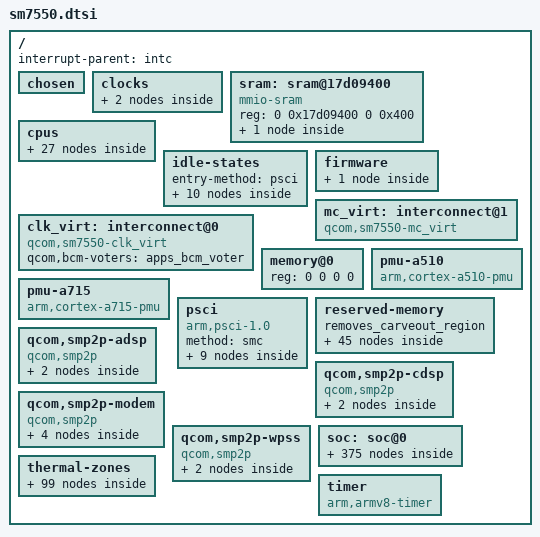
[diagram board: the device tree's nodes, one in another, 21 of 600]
// SPDX-License-Identifier: BSD-3-Clause
/*
 * Copyright (c) 2025, Aditya Choudhury <mail@inferno0230.in>
 */

#include <dt-bindings/clock/qcom,dsi-phy-28nm.h>
#include <dt-bindings/clock/qcom,rpmh.h>
#include <dt-bindings/clock/qcom,sm7550-camcc.h>
#include <dt-bindings/clock/qcom,sm7550-dispcc.h>
#include <dt-bindings/clock/qcom,sm7550-gcc.h>
#include <dt-bindings/clock/qcom,sm7550-gpucc.h>
#include <dt-bindings/clock/qcom,sm7550-tcsr.h>
#include <dt-bindings/clock/qcom,sm7550-videocc.h>
#include <dt-bindings/dma/qcom-gpi.h>
#include <dt-bindings/gpio/gpio.h>
#include <dt-bindings/interconnect/qcom,icc.h>
#include <dt-bindings/interconnect/qcom,sm7550-rpmh.h>
#include <dt-bindings/interrupt-controller/arm-gic.h>
#include <dt-bindings/mailbox/qcom-ipcc.h>
#include <dt-bindings/phy/phy-qcom-qmp.h>
#include <dt-bindings/power/qcom,rpmhpd.h>
#include <dt-bindings/soc/qcom,gpr.h>
#include <dt-bindings/soc/qcom,rpmh-rsc.h>
#include <dt-bindings/sound/qcom,q6dsp-lpass-ports.h>
#include <dt-bindings/thermal/thermal.h>

/ {
	interrupt-parent = <&intc>;

	#address-cells = <2>;
	#size-cells = <2>;

	chosen { };

    clocks {
        xo_board: xo_board {
			compatible = "fixed-clock";
			clock-frequency = <76800000>;
			clock-output-names = "xo_board";
			#clock-cells = <0>;
		};

		sleep_clk: sleep_clk {
			compatible = "fixed-clock";
			clock-frequency = <32000>;
			clock-output-names = "sleep_clk";
			#clock-cells = <0>;
		};
    };

	sram: sram@17d09400 {
		compatible = "mmio-sram";
		reg = <0 0x17d09400 0 0x400>;
		ranges = <0 0 0 0x17d09400 0 0x400>;
		#address-cells = <2>;
		#size-cells = <2>;

		cpu_scp_lpri: scmi-shmem@0 {
			compatible = "arm,scmi-shmem";
			reg = <0 0 0 0x400>;
		};
	};

	cpus {
		#address-cells = <2>;
		#size-cells = <0>;

		cpu0: cpu@0 {
			device_type = "cpu";
			compatible = "arm,cortex-a510";
			reg = <0x0 0x0>;
            clocks = <&cpufreq_hw 0>;
			enable-method = "psci";
			next-level-cache = <&l2_0>;
			power-domains = <&cpu_pd0>;
			power-domain-names = "psci";
			qcom,freq-domain = <&cpufreq_hw 0>;
			next-level-cache = <&l2_0>;
			capacity-dmips-mhz = <1024>;
			dynamic-power-coefficient = <100>;
			#cooling-cells = <2>;
			l2_0: l2-cache {
				compatible = "cache";
				cache-level = <2>;
				cache-unified;
				next-level-cache = <&l3_0>;
				l3_0: l3-cache {
					compatible = "cache";
					cache-level = <3>;
					cache-unified;
				};
			};
		};

		cpu1: cpu@100 {
			device_type = "cpu";
			compatible = "arm,cortex-a510";
			reg = <0x0 0x100>;
			enable-method = "psci";
			clocks = <&cpufreq_hw 0>;
			power-domains = <&cpu_pd1>;
			power-domain-names = "psci";
			qcom,freq-domain = <&cpufreq_hw 0>;
			next-level-cache = <&l2_0>;
			capacity-dmips-mhz = <1024>;
			dynamic-power-coefficient = <100>;
			#cooling-cells = <2>;
		};

		cpu2: cpu@200 {
			device_type = "cpu";
			compatible = "arm,cortex-a510";
			reg = <0x0 0x200>;
			enable-method = "psci";
			clocks = <&cpufreq_hw 0>;
			power-domains = <&CPU_PD2>;
			power-domain-names = "psci";
			qcom,freq-domain = <&cpufreq_hw 0>;
			next-level-cache = <&l2_2>;
			capacity-dmips-mhz = <1024>;
			dynamic-power-coefficient = <100>;
			#cooling-cells = <2>;
			l2_2: l2-cache {
				compatible = "cache";
				cache-level = <2>;
				cache-unified;
				next-level-cache = <&l3_0>;
			};
		};

		cpu3: cpu@300 {
			device_type = "cpu";
			compatible = "arm,cortex-a510";
			reg = <0x0 0x300>;
			enable-method = "psci";
			clocks = <&cpufreq_hw 0>;
			power-domains = <&cpu_pd3>;
			power-domain-names = "psci";
			qcom,freq-domain = <&cpufreq_hw 0>;
			next-level-cache = <&l2_2>;
			capacity-dmips-mhz = <1024>;
			dynamic-power-coefficient = <100>;
			#cooling-cells = <2>;
		};

		cpu4: cpu@400 {
			device_type = "cpu";
			compatible = "arm,cortex-a715";
			reg = <0x0 0x400>;
			enable-method = "psci";
			clocks = <&cpufreq_hw 1>;
			power-domains = <&cpu_pd4>;
			power-domain-names = "psci";
			qcom,freq-domain = <&cpufreq_hw 1>;
			next-level-cache = <&l2_4>;
			capacity-dmips-mhz = <1843>;
			dynamic-power-coefficient = <226>;
			#cooling-cells = <2>;
			l2_4: l2-cache {
				compatible = "cache";
				cache-level = <2>;
				cache-unified;
				next-level-cache = <&l3_0>;
			};
		};

		cpu5: cpu@500 {
			device_type = "cpu";
			compatible = "arm,cortex-a715";
			reg = <0x0 0x500>;
			enable-method = "psci";
			clocks = <&cpufreq_hw 1>;
			power-domains = <&cpu_pd5>;
			power-domain-names = "psci";
			qcom,freq-domain = <&cpufreq_hw 1>;
			next-level-cache = <&l2_5>;
			capacity-dmips-mhz = <1843>;
			dynamic-power-coefficient = <226>;
			#cooling-cells = <2>;
			l2_5: l2-cache {
				compatible = "cache";
				cache-level = <2>;
				cache-unified;
				next-level-cache = <&l3_0>;
			};
		};

		cpu6: cpu@600 {
			device_type = "cpu";
			compatible = "arm,cortex-a715";
			reg = <0x0 0x600>;
			enable-method = "psci";
			clocks = <&cpufreq_hw 1>;
			power-domains = <&cpu_pd6>;
			power-domain-names = "psci";
			qcom,freq-domain = <&cpufreq_hw 1>;
			next-level-cache = <&l2_6>;
			capacity-dmips-mhz = <1843>;
			dynamic-power-coefficient = <226>;
			#cooling-cells = <2>;
			l2_6: l2-cache {
				compatible = "cache";
				cache-level = <2>;
				cache-unified;
				next-level-cache = <&l3_0>;
			};
		};

		cpu7: cpu@700 {
			device_type = "cpu";
			compatible = "arm,cortex-a715";
			reg = <0x0 0x700>;
			enable-method = "psci";
			clocks = <&cpufreq_hw 2>;
			power-domains = <&cpu_pd7>;
			power-domain-names = "psci";
			qcom,freq-domain = <&cpufreq_hw 2>;
			next-level-cache = <&l2_7>;
			capacity-dmips-mhz = <1853>;
			dynamic-power-coefficient = <245>;
			#cooling-cells = <2>;
			l2_7: l2-cache {
				compatible = "cache";
				cache-level = <2>;
				cache-unified;
				next-level-cache = <&l3_0>;
			};
		};

		cpu-map {
			cluster0 {
				core0 {
					cpu = <&cpu0>;
				};

				core1 {
					cpu = <&cpu1>;
				};

				core2 {
					cpu = <&cpu2>;
				};

				core3 {
					cpu = <&cpu3>;
				};
			};

			cluster1 {
				core0 {
					cpu = <&cpu4>;
				};

				core1 {
					cpu = <&cpu5>;
				};

				core2 {
					cpu = <&cpu6>;
				};
			};

			cluster2 {
				core0 {
					cpu = <&cpu7>;
				};
			};
		};
	};

    idle-states {
		entry-method = "psci";

		silver_cpu_sleep_0: cpu-sleep-0-0 {
			compatible = "arm,idle-state";
			idle-state-name = "silver-power-collapse";
			entry-latency-us = <250>;
			exit-latency-us = <900>;
			min-residency-us = <3200>;
			arm,psci-suspend-param = <0x40000003>;
			local-timer-stop;
		};

		silver_cpu_sleep_1: cpu-sleep-0-1 {
			compatible = "arm,idle-state";
			idle-state-name = "silver-rail-power-collapse";
			entry-latency-us = <550>;
			exit-latency-us = <750>;
			min-residency-us = <6700>;
			arm,psci-suspend-param = <0x40000004>;
			local-timer-stop;
		};

		gold_cpu_sleep_0: cpu-sleep-1-0 {
			compatible = "arm,idle-state";
			idle-state-name = "gold-power-collapse";
			entry-latency-us = <400>;
			exit-latency-us = <1100>;
			min-residency-us = <4011>;
			arm,psci-suspend-param = <0x40000003>;
			local-timer-stop;
		};

		gold_cpu_sleep_1: cpu-sleep-1-1 {
			compatible = "arm,idle-state";
			idle-state-name = "gold-rail-power-collapse";
			entry-latency-us = <600>;
			exit-latency-us = <1300>;
			min-residency-us = <8136>;
			arm,psci-suspend-param = <0x40000004>;
			local-timer-stop;
		};

		gold_plus_cpu_sleep_0: cpu-sleep-2-0 {  /* C3 */
			compatible = "arm,idle-state";
			idle-state-name = "gold-plus-power-collapse";
			entry-latency-us = <450>;
			exit-latency-us = <1200>;
			min-residency-us = <6230>;
			arm,psci-suspend-param = <0x40000003>;
			local-timer-stop;
		};

		gold_plus_cpu_sleep_1: cpu-sleep-2-1 {  /* C4 */
			compatible = "arm,idle-state";
			idle-state-name = "gold-plus-rail-power-collapse";
			entry-latency-us = <500>;
			exit-latency-us = <1350>;
			min-residency-us = <7480>;
			arm,psci-suspend-param = <0x40000004>;
			local-timer-stop;
		};

        domain_idle_states {
            cluster_sleep_0: cluster-sleep-0 {
                compatible = "domain-idle-state";
                idle-state-name = "domain-idle-state";
                entry-latency-us = <750>;
                exit-latency-us = <2350>;
                min-residency-us = <9144>;
                arm,psci-suspend-param = <0x41000044>;
            };

            cluster_sleep_1: cluster-sleep-1 {
                compatible = "domain-idle-state";
                idle-state-name = "cx-ret";
                entry-latency-us = <1561>;
                exit-latency-us = <2801>;
                min-residency-us = <8550>;
                arm,psci-suspend-param = <0x41001344>;
            };

            cluster_sleep_2: cluster-sleep-2 {
                compatible = "domain-idle-state";
                idle-state-name = "domain-idle-state";
                entry-latency-us = <2800>;
                exit-latency-us = <4400>;
                min-residency-us = <10150>;
                arm,psci-suspend-param = <0x4100b344>;
            };

        };
	};

    firmware {
        scm: scm {
            compatible = "qcom,scm-sm7550", "qcom,scm";
            qcom,dload-mode = <&tcsr 0x19000>;
        };
    };

	clk_virt: interconnect@0 {
		compatible = "qcom,sm7550-clk_virt";
		#interconnect-cells = <1>;
		qcom,bcm-voters = <&apps_bcm_voter>;
	};

	mc_virt: interconnect@1 {
		compatible = "qcom,sm7550-mc_virt";
		#interconnect-cells = <1>;
		qcom,bcm-voters = <&apps_bcm_voter>, <&disp_bcm_voter>;
	};

	memory@0 {
		device_type = "memory";
		/* We expect the bootloader to fill in the size */
		reg = <0 0 0 0>;
	};

	pmu-a510 {
		compatible = "arm,cortex-a510-pmu";
		interrupts = <GIC_PPI 7 IRQ_TYPE_LEVEL_LOW &ppi_cluster0>;
	};

	pmu-a715 {
		compatible = "arm,cortex-a715-pmu";
		interrupts = <GIC_PPI 7 IRQ_TYPE_LEVEL_LOW &ppi_cluster1>;
	};

	psci {
		compatible = "arm,psci-1.0";
		method = "smc";

		cpu_pd0: power-domain-cpu0 {
			#power-domain-cells = <0>;
			power-domains = <&cluster_pd>;
            domain-idle-states = <&silver_cpu_sleep_0>, <&silver_cpu_sleep_1>;
		};

		cpu_pd1: power-domain-cpu1 {
			#power-domain-cells = <0>;
			power-domains = <&cluster_pd>;
            domain-idle-states = <&silver_cpu_sleep_0>, <&silver_cpu_sleep_1>;
		};

		cpu_pd2: power-domain-cpu2 {
			#power-domain-cells = <0>;
			power-domains = <&cluster_pd>;
            domain-idle-states = <&silver_cpu_sleep_0>, <&silver_cpu_sleep_1>;
		};

		cpu_pd3: power-domain-cpu3 {
			#power-domain-cells = <0>;
			power-domains = <&cluster_pd>;
            domain-idle-states = <&silver_cpu_sleep_0>, <&silver_cpu_sleep_1>;
		};

		cpu_pd4: power-domain-cpu4 {
			#power-domain-cells = <0>;
			power-domains = <&cluster_pd>;
            domain-idle-states = <&gold_cpu_sleep_0>, <&gold_cpu_sleep_1>;
		};

		cpu_pd5: power-domain-cpu5 {
			#power-domain-cells = <0>;
			power-domains = <&cluster_pd>;
            domain-idle-states = <&gold_cpu_sleep_0>, <&gold_cpu_sleep_1>;
		};

		cpu_pd6: power-domain-cpu6 {
			#power-domain-cells = <0>;
			power-domains = <&cluster_pd>;
            domain-idle-states = <&gold_cpu_sleep_0>, <&gold_cpu_sleep_1>;
		};

		cpu_pd7: power-domain-cpu7 {
			#power-domain-cells = <0>;
			power-domains = <&cluster_pd>;
            domain-idle-states = <&gold_plus_cpu_sleep_0>, <&gold_plus_cpu_sleep_1>;
		};

		cluster_pd: power-domain-cluster {
			#power-domain-cells = <0>;
			domain-idle-states = <&cluster_sleep_0>, <&cluster_sleep_1>, <&cluster_sleep_2>;
		};
	};

    reserved-memory {
        #address-cells = <2>;
        #size-cells = <2>;
        ranges;
        removes_carveout_region;

        gunyah_hyp_mem: gunyah_hyp_region@80000000 {
            no-map;
            reg = <0x0 0x80000000 0x0 0xa00000>;
        };

        cpusys_vm_mem: cpusys_vm_region@80a00000 {
            no-map;
            reg = <0x0 0x80a00000 0x0 0x400000>;
        };

        hyp_tags_mem: hyp_tags_region@80e00000 {
            no-map;
            reg = <0x0 0x80e00000 0x0 0x3d0000>;
        };

        hyp_reserved_mem: hyp_reserved_region@811d0000 {
            no-map;
            reg = <0x0 0x811d0000 0x0 0x30000>;
        };

        xbl_dtlog_mem: xbl_dtlog_region@81a00000 {
            no-map;
            reg = <0x0 0x81a00000 0x0 0x40000>;
        };

        xbl_ramdump_mem: xbl_ramdump_region@81a40000 {
            no-map;
            reg = <0x0 0x81a40000 0x0 0x1c0000>;
        };

        aop_image_mem: aop_image_region@81c00000 {
            no-map;
            reg = <0x0 0x81c00000 0x0 0x60000>;
        };

        aop_cmd_db_mem: aop_cmd_db_region@81c60000 {
            compatible = "qcom,cmd-db";
            no-map;
            reg = <0x0 0x81c60000 0x0 0x20000>;
        };

        aop_config_mem: aop_config_region@81c80000 {
            no-map;
            reg = <0x0 0x81c80000 0x0 0x20000>;
        };

        tme_crash_dump_mem: tme_crash_dump_region@81ca0000 {
            no-map;
            reg = <0x0 0x81ca0000 0x0 0x40000>;
        };

        tme_log_mem: tme_log_region@81ce0000 {
            no-map;
            reg = <0x0 0x81ce0000 0x0 0x4000>;
        };

        uefi_log_mem: uefi_log_region@81ce4000 {
            no-map;
            reg = <0x0 0x81ce4000 0x0 0x10000>;
        };

        chipinfo_mem: chipinfo_region@81cf4000 {
            no-map;
            reg = <0x0 0x81cf4000 0x0 0x1000>;
        };

        smem_mem: smem_region@81d00000 {
            no-map;
            reg = <0x0 0x81d00000 0x0 0x200000>;
        };

        adsp_mhi_mem: adsp_mhi_region@81f00000 {
            no-map;
            reg = <0x0 0x81f00000 0x0 0x20000>;
        };

        global_sync_mem: global_sync_region@82600000 {
            no-map;
            reg = <0x0 0x82600000 0x0 0x100000>;
        };

        tz_stat_mem: tz_stat_region@82700000 {
            no-map;
            reg = <0x0 0x82700000 0x0 0x100000>;
        };

        wlan_msa_moselle_mem: wlan_msa_moselle_region@82800000 {
            no-map;
            reg = <0x0 0x82800000 0x0 0xc00000>;
        };

        mpss_mem: mpss_region@8a800000 {
            no-map;
            reg = <0x0 0x8a800000 0x0 0x11800000>;
        };

        q6_mpss_dtb_mem: q6_mpss_dtb_region@9c000000 {
            no-map;
            reg = <0x0 0x9c000000 0x0 0x80000>;
        };

        ipa_fw_mem: ipa_fw_region@9c080000 {
            no-map;
            reg = <0x0 0x9c080000 0x0 0x10000>;
        };

        ipa_gsi_mem: ipa_gsi_region@9c090000 {
            no-map;
            reg = <0x0 0x9c090000 0x0 0xa000>;
        };

        gpu_microcode_mem: gpu_microcode_region@9c09a000 {
            no-map;
            reg = <0x0 0x9c09a000 0x0 0x2000>;
        };

        q6_adsp_dtb_mem: q6_adsp_dtb_region@9c180000 {
            no-map;
            reg = <0x0 0x9c180000 0x0 0x80000>;
        };

        adsp_mem: adsp_region@9c200000 {
            no-map;
            reg = <0x0 0x9c200000 0x0 0x2900000>;
        };

        camera_mem: camera_region@a1b00000 {
            no-map;
            reg = <0x0 0xa1b00000 0x0 0x800000>;
        };

        video_mem: video_region@9f000000 {
            no-map;
            reg = <0x0 0x9f000000 0x0 0x700000>;
        };

        wpss_moselle_mem: wpss_moselle_region@9f700000 {
            no-map;
            reg = <0x0 0x9f700000 0x0 0x1900000>;
        };

        cdsp_mem: cdsp_region@a1000000 {
            no-map;
            reg = <0x0 0xa1000000 0x0 0xa80000>;
        };

        q6_cdsp_dtb_mem: q6_cdsp_dtb_region@a1a80000 {
            no-map;
            reg = <0x0 0xa1a80000 0x0 0x80000>;
        };

        tz_reserved_mem: tz_reserved_region@d8000000 {
            no-map;
            reg = <0x0 0xd8000000 0x0 0x100000>;
        };

        xbl_sc_mem: xbl_sc_region@d8100000 {
            no-map;
            reg = <0x0 0xd8100000 0x0 0x40000>;
        };

        cpucp_fw_mem: cpucp_fw_region@d8140000 {
            no-map;
            reg = <0x0 0xd8140000 0x0 0x1c0000>;
        };

        qtee_mem: qtee_region@d8300000 {
            no-map;
            reg = <0x0 0xd8300000 0x0 0x500000>;
        };

        ta_mem: ta_region@d8800000 {
            no-map;
            reg = <0x0 0xd8800000 0x0 0x1a00000>;
        };

        tz_tags_mem: tz_tags_region@da200000 {
            no-map;
            reg = <0x0 0xda200000 0x0 0x680000>;
        };

        trust_ui_vm_mem: trust_ui_vm_region@f3800000 {
            no-map;
            reg = <0x0 0xf3800000 0x0 0x40ee000>;
        };

        trust_ui_vm_dump: trust_ui_vm_dump@0xf78ee000 {
            no-map;
            reg = <0x0 0xf78ee000 0x0 0x1000>;
        };

        trust_ui_vm_qrtr: trust_ui_vm_qrtr@0xf78ef000 {
            no-map;
            reg = <0x0 0xf78ef000 0x0 0x9000>;
        };

        trust_ui_vm_vblk0_ring: trust_ui_vm_vblk0_ring@0xf78f8000 {
            no-map;
            reg = <0x0 0xf78f8000 0x0 0x4000>;
            gunyah-label = <0x11>;
        };

        trust_ui_vm_vblk1_ring: trust_ui_vm_vblk1_ring@0xf78fc000 {
            no-map;
            reg = <0x0 0xf78fc000 0x0 0x4000>;
            gunyah-label = <0x10>;
        };

        trust_ui_vm_swiotlb: trust_ui_vm_swiotlb@0xf7900000 {
            no-map;
            reg = <0x0 0xf7900000 0x0 0x100000>;
            gunyah-label = <0x12>;
        };

        oem_vm_vblk0_ring: oem_vm_vblk0_ring@f7afc000 {
            no-map;
            reg = <0x0 0xf7afc000 0x0 0x4000>;
            gunyah-label = <0x13>;
        };

        oem_vm_swiotlb: oem_vm_swiotlb@f7b00000 {
            no-map;
            reg = <0x0 0xf7b00000 0x0 0x100000>;
            gunyah-label = <0x14>;
        };

        oem_vm_mem: oem_vm_region@f7c00000 {
            compatible = "shared-dma-pool";
            reg = <0x0 0xf7c00000 0x0 0x4800000>;
            reusable;
            alignment = <0x0 0x400000>;
        };
    };

	qcom,smp2p-adsp {
		compatible = "qcom,smp2p";
		qcom,smem = <443>, <429>;
		interrupt-parent = <&ipcc_mproc>;
		interrupts = <IPCC_CLIENT_LPASS 
                      IPCC_MPROC_SIGNAL_SMP2P
			          IRQ_TYPE_EDGE_RISING>;
		mboxes = <&ipcc_mproc IPCC_CLIENT_LPASS
			  IPCC_MPROC_SIGNAL_SMP2P>;
		qcom,local-pid = <0>;
		qcom,remote-pid = <2>;

		adsp_smp2p_out: master-kernel {
			qcom,entry-name = "master-kernel";
			#qcom,smem-state-cells = <1>;
		};

		adsp_smp2p_in: slave-kernel {
			qcom,entry-name = "slave-kernel";
			interrupt-controller;
			#interrupt-cells = <2>;
		};
	};

	qcom,smp2p-cdsp {
		compatible = "qcom,smp2p";
		qcom,smem = <94>, <432>;
		interrupt-parent = <&ipcc_mproc>;
		interrupts = <IPCC_CLIENT_CDSP IPCC_MPROC_SIGNAL_SMP2P
			      IRQ_TYPE_EDGE_RISING>;
		mboxes = <&ipcc_mproc IPCC_CLIENT_CDSP IPCC_MPROC_SIGNAL_SMP2P>;
		qcom,local-pid = <0>;
		qcom,remote-pid = <5>;

		cdsp_smp2p_out: master-kernel {
			qcom,entry-name = "master-kernel";
			#qcom,smem-state-cells = <1>;
		};

		cdsp_smp2p_in: slave-kernel {
			qcom,entry-name = "slave-kernel";
			interrupt-controller;
			#interrupt-cells = <2>;
		};
	};

	qcom,smp2p-modem {
		compatible = "qcom,smp2p";
		qcom,smem = <435>, <428>;
		interrupt-parent = <&ipcc_mproc>;
		interrupts = <IPCC_CLIENT_MPSS IPCC_MPROC_SIGNAL_SMP2P
			      IRQ_TYPE_EDGE_RISING>;
		mboxes = <&ipcc_mproc IPCC_CLIENT_MPSS IPCC_MPROC_SIGNAL_SMP2P>;
		qcom,local-pid = <0>;
		qcom,remote-pid = <1>;

		modem_smp2p_out: master-kernel {
			qcom,entry-name = "master-kernel";
			#qcom,smem-state-cells = <1>;
		};

		modem_smp2p_in: slave-kernel {
			qcom,entry-name = "slave-kernel";
			interrupt-controller;
			#interrupt-cells = <2>;
		};

		smp2p_ipa_out: ipa-ap-to-modem {
			qcom,entry-name = "ipa";
			#qcom,smem-state-cells = <1>;
		};

		smp2p_ipa_in: ipa-modem-to-ap {
			qcom,entry-name = "ipa";
			interrupt-controller;
			#interrupt-cells = <2>;
		};
	};
	qcom,smp2p-wpss {
		compatible = "qcom,smp2p";
		qcom,smem = <617>, <616>;
		interrupt-parent = <&ipcc_mproc>;
		interrupts = <IPCC_CLIENT_WPSS IPCC_MPROC_SIGNAL_SMP2P
			IRQ_TYPE_EDGE_RISING>;
		mboxes = <&ipcc_mproc IPCC_CLIENT_WPSS IPCC_MPROC_SIGNAL_SMP2P>;
		qcom,local-pid = <0>;
		qcom,remote-pid = <13>;

		wpss_smp2p_out: master-kernel {
			qcom,entry-name = "master-kernel";
			#qcom,smem-state-cells = <1>;
		};

		wpss_smp2p_in: slave-kernel {
			qcom,entry-name = "slave-kernel";
			interrupt-controller;
			#interrupt-cells = <2>;
		};
	};

    soc: soc@0 {
        gcc: clock-controller@100000 {
            compatible = "qcom,sm7550-gcc";
            reg = <0 0x100000 0 0x1f4200>;
            clocks = <&rpmhcc RPMH_CXO_CLK>,
                <&pcie_0_pipe_clk>,
                <&pcie_1_phy_aux_clk>,
                <&pcie_1_pipe_clk>,
                <&sleep_clk>,
                <&ufs_phy_rx_symbol_0_clk>,
                <&ufs_phy_rx_symbol_1_clk>,
                <&ufs_phy_tx_symbol_0_clk>,
                <&usb3_phy_wrapper_gcc_usb30_pipe_clk>;
            #clock-cells = <1>;
            #reset-cells = <1>;
        };

        ipcc: mailbox@408000 {
            compatible = "qcom,sm7550-ipcc";
            reg = <0 0x408000 0 0x1000>;
            interrupts = <GIC_SPI 229 IRQ_TYPE_LEVEL_HIGH 0>;
            interrupt-controller;
            #interrupt-cells = <3>;
            #mbox-cells = <2>;
        };

        gpi_dma0: dma-controller@800000  {
            compatible = "qcom,sm7550-gpi-dma";
            #dma-cells = <5>;
            reg = <0 0x800000 0 0x60000>;
            interrupts = <GIC_SPI 588 IRQ_TYPE_LEVEL_HIGH>,
                <GIC_SPI 589 IRQ_TYPE_LEVEL_HIGH>,
                <GIC_SPI 590 IRQ_TYPE_LEVEL_HIGH>,
                <GIC_SPI 591 IRQ_TYPE_LEVEL_HIGH>,
                <GIC_SPI 592 IRQ_TYPE_LEVEL_HIGH>,
                <GIC_SPI 593 IRQ_TYPE_LEVEL_HIGH>,
                <GIC_SPI 594 IRQ_TYPE_LEVEL_HIGH>,
                <GIC_SPI 595 IRQ_TYPE_LEVEL_HIGH>,
                <GIC_SPI 596 IRQ_TYPE_LEVEL_HIGH>,
                <GIC_SPI 597 IRQ_TYPE_LEVEL_HIGH>,
                <GIC_SPI 598 IRQ_TYPE_LEVEL_HIGH>,
                <GIC_SPI 599 IRQ_TYPE_LEVEL_HIGH>;
            dma-channels = <12>;
            dma-channel-mask = <0x1E>;
            iommus = <&apps_smmu 0x436 0x0>;
            dma-coherent;
            status = "disabled";
        };

        gpi_dma1: dma-controller@a00000  {
            compatible = "qcom,sm7550-gpi-dma";
            #dma-cells = <5>;
            reg = <0 0xa00000 0 0x60000>;
            interrupts = <GIC_SPI 279 IRQ_TYPE_LEVEL_HIGH 0>,
                <GIC_SPI 280 IRQ_TYPE_LEVEL_HIGH 0>,
                <GIC_SPI 281 IRQ_TYPE_LEVEL_HIGH 0>,
                <GIC_SPI 282 IRQ_TYPE_LEVEL_HIGH 0>,
                <GIC_SPI 283 IRQ_TYPE_LEVEL_HIGH 0>,
                <GIC_SPI 284 IRQ_TYPE_LEVEL_HIGH 0>,
                <GIC_SPI 293 IRQ_TYPE_LEVEL_HIGH 0>,
                <GIC_SPI 294 IRQ_TYPE_LEVEL_HIGH 0>,
                <GIC_SPI 295 IRQ_TYPE_LEVEL_HIGH 0>,
                <GIC_SPI 296 IRQ_TYPE_LEVEL_HIGH 0>,
                <GIC_SPI 297 IRQ_TYPE_LEVEL_HIGH 0>,
                <GIC_SPI 298 IRQ_TYPE_LEVEL_HIGH 0>;
            dma-channels = <12>;
            dma-channel-mask = <0x3f>;
            iommus = <&apps_smmu 0x36 0x0>;
            dma-coherent;
            status = "disabled";
        };

        qupv3_id_0: geniqup@8c0000 {
            compatible = "qcom,geni-se-qup";
            reg = <0 0x8c0000 0 0x2000>;
			ranges;
            clock-names = "m-ahb", "s-ahb";
            clocks = <&gcc GCC_QUPV3_WRAP_0_M_AHB_CLK>,
                <&gcc GCC_QUPV3_WRAP_0_S_AHB_CLK>;
            iommus = <&apps_smmu 0x423 0x0>;
            dma-coherent;
            #address-cells = <2>;
			#size-cells = <2>;
            status = "disabled";

            i2c0: i2c@880000 {
                compatible = "qcom,geni-i2c";
                reg = <0 0x880000 0 0x4000>;
                interrupts = <GIC_SPI 373 IRQ_TYPE_LEVEL_HIGH 0>;
                clock-names = "se";
                clocks = <&gcc GCC_QUPV3_WRAP0_S0_CLK>;
                interconnects = <&clk_virt MASTER_QUP_CORE_0 &clk_virt SLAVE_QUP_CORE_0>,
                                <&gem_noc MASTER_APPSS_PROC &config_noc SLAVE_QUP_0>,
                                <&aggre2_noc MASTER_QUP_0 &mc_virt SLAVE_EBI1>;
                interconnect-names = "qup-core", "qup-config", "qup-memory";
                dmas = <&gpi_dma0 0 0 QCOM_GPI_I2C>,
                    <&gpi_dma0 1 0 QCOM_GPI_I2C>;
                dma-names = "tx", "rx";
                pinctrl-0 = <&qup_i2c0_data_clk>;
                pinctrl-names = "default", "sleep";
                #address-cells = <1>;
                #size-cells = <0>;

                status = "disabled";
            };

            spi0: spi@880000 {
                compatible = "qcom,geni-spi";
                reg = <0 0x880000 0 0x4000>;
                interrupts = <GIC_SPI 373 IRQ_TYPE_LEVEL_HIGH 0>;
                clock-names = "se";
                clocks = <&gcc GCC_QUPV3_WRAP0_S0_CLK>;
                interconnects =
                <&clk_virt MASTER_QUP_CORE_0 &clk_virt SLAVE_QUP_CORE_0>,
                <&gem_noc MASTER_APPSS_PROC &config_noc SLAVE_QUP_0>,
                <&aggre2_noc MASTER_QUP_0 &mc_virt  SLAVE_EBI1>;
                interconnect-names = "qup-core", "qup-config", "qup-memory";
                dmas = <&gpi_dma0 0 0 QCOM_GPI_SPI>,
                    <&gpi_dma0 1 0 QCOM_GPI_SPI>;
                dma-names = "tx", "rx";
                pinctrl-names = "default", "sleep";
                pinctrl-0 = <&qup_spi0_data_clk>, <&qup_spi0_cs>;

                #address-cells = <1>;
                #size-cells = <0>;

                status = "disabled";
            };

            i2c1: i2c@884000 {
                compatible = "qcom,geni-i2c";
                reg = <0 0x884000 0 0x4000>;
                interrupts = <GIC_SPI 583 IRQ_TYPE_LEVEL_HIGH 0>;
                clock-names = "se";
                clocks = <&gcc GCC_QUPV3_WRAP0_S1_CLK>;
                interconnects = 
                <&clk_virt MASTER_QUP_CORE_0 &clk_virt SLAVE_QUP_CORE_0>,
    			<&gem_noc MASTER_APPSS_PROC &config_noc SLAVE_QUP_0>,
	    		<&aggre2_noc MASTER_QUP_0 &mc_virt  SLAVE_EBI1>;
                interconnect-names = "qup-core", "qup-config", "qup-memory";
                dmas = <&gpi_dma0 0 1 QCOM_GPI_I2C>,
                    <&gpi_dma0 1 1 QCOM_GPI_I2C>;
                dma-names = "tx", "rx";
                pinctrl-0 = <&qup_i2c1_data_clk>;
                pinctrl-names = "default", "sleep";
                #address-cells = <1>;
                #size-cells = <0>;

                status = "disabled";
            };

            spi1: spi@884000 {
                compatible = "qcom,geni-spi";
                reg = <0 884000 0 0x4000>;
                interrupts = <GIC_SPI 583 IRQ_TYPE_LEVEL_HIGH 0>;
                clock-names = "se";
                clocks = <&gcc GCC_QUPV3_WRAP0_S1_CLK>;
                interconnects =
		    	<&clk_virt MASTER_QUP_CORE_0 &clk_virt SLAVE_QUP_CORE_0>,
		    	<&gem_noc MASTER_APPSS_PROC &config_noc SLAVE_QUP_0>,
		    	<&aggre2_noc MASTER_QUP_0 &mc_virt  SLAVE_EBI1>;
                interconnect-names = "qup-core", "qup-config", "qup-memory";
                dmas = <&gpi_dma0 0 1 QCOM_GPI_SPI>,
                    <&gpi_dma0 1 1 QCOM_GPI_SPI>;
                dma-names = "tx", "rx";
                pinctrl-names = "default", "sleep";
                pinctrl-0 = <&qup_spi1_data_clk>, <&qup_spi1_cs>;

                #address-cells = <1>;
                #size-cells = <0>;

                status = "disabled";
            };

            i2c2: i2c@888000 {
                compatible = "qcom,geni-i2c";
                reg = <0 888000 0 0x4000>;
                interrupts = <GIC_SPI 584 IRQ_TYPE_LEVEL_HIGH 0>;
                clock-names = "se";
                clocks = <&gcc GCC_QUPV3_WRAP0_S2_CLK>;
                interconnects = 
			    <&clk_virt MASTER_QUP_CORE_0 &clk_virt SLAVE_QUP_CORE_0>,
			    <&gem_noc MASTER_APPSS_PROC &config_noc SLAVE_QUP_0>,
			    <&aggre2_noc MASTER_QUP_0 &mc_virt  SLAVE_EBI1>;
                interconnect-names = "qup-core", "qup-config", "qup-memory";
                dmas = <&gpi_dma0 0 2 QCOM_GPI_I2C>,
                    <&gpi_dma0 1 2 QCOM_GPI_I2C>;
                dma-names = "tx", "rx";
                pinctrl-0 = <&qup_i2c2_data_clk>;
                pinctrl-names = "default", "sleep";
                #address-cells = <1>;
                #size-cells = <0>;

                status = "disabled";
            };

            spi2: spi@888000 {
                compatible = "qcom,geni-spi";
                reg = <0 888000 0 0x4000>;
                interrupts = <GIC_SPI 584 IRQ_TYPE_LEVEL_HIGH 0>;
                clock-names = "se";
                clocks = <&gcc GCC_QUPV3_WRAP0_S2_CLK>;
                interconnects =
                <&clk_virt MASTER_QUP_CORE_0 &clk_virt SLAVE_QUP_CORE_0>,
                <&gem_noc MASTER_APPSS_PROC &config_noc SLAVE_QUP_0>,
                <&aggre2_noc MASTER_QUP_0 &mc_virt  SLAVE_EBI1>;
                interconnect-names = "qup-core", "qup-config", "qup-memory";
                dmas = <&gpi_dma0 0 2 QCOM_GPI_SPI>,
                    <&gpi_dma0 1 2 QCOM_GPI_SPI>;
                dma-names = "tx", "rx";
                pinctrl-names = "default", "sleep";
                pinctrl-0 = <&qup_spi2_data_clk>, <&qup_spi2_cs>;

                #address-cells = <1>;
                #size-cells = <0>;

                status = "disabled";
            };

            i2c3: i2c@88c000 {
                compatible = "qcom,geni-i2c";
                reg = <0 88c000 0 0x4000>;
                interrupts = <GIC_SPI 585 IRQ_TYPE_LEVEL_HIGH 0>;
                clock-names = "se";
                clocks = <&gcc GCC_QUPV3_WRAP0_S3_CLK>;
                interconnects = 
                <&clk_virt MASTER_QUP_CORE_0 &clk_virt SLAVE_QUP_CORE_0>,
                <&gem_noc MASTER_APPSS_PROC &config_noc SLAVE_QUP_0>,
                <&aggre2_noc MASTER_QUP_0 &mc_virt  SLAVE_EBI1>;
                interconnect-names = "qup-core", "qup-config", "qup-memory";
                dmas = <&gpi_dma0 0 3 QCOM_GPI_I2C>,
                    <&gpi_dma0 1 3 QCOM_GPI_I2C>;
                dma-names = "tx", "rx";
                pinctrl-0 = <&qup_i2c3_data_clk>;
                pinctrl-names = "default", "sleep";
                #address-cells = <1>;
                #size-cells = <0>;

                status = "disabled";
            };

            spi3: spi@88c000 {
                compatible = "qcom,geni-spi";
                reg = <0 88c000 0 0x4000>;
                interrupts = <GIC_SPI 585 IRQ_TYPE_LEVEL_HIGH 0>;
                clock-names = "se";
                clocks = <&gcc GCC_QUPV3_WRAP0_S3_CLK>;
                interconnects =
                <&clk_virt MASTER_QUP_CORE_0 &clk_virt SLAVE_QUP_CORE_0>,
                <&gem_noc MASTER_APPSS_PROC &config_noc SLAVE_QUP_0>,
                <&aggre2_noc MASTER_QUP_0 &mc_virt  SLAVE_EBI1>;
                interconnect-names = "qup-core", "qup-config", "qup-memory";
                dmas = <&gpi_dma0 0 3 QCOM_GPI_SPI>,
                    <&gpi_dma0 1 3 QCOM_GPI_SPI>;
                dma-names = "tx", "rx";
                pinctrl-names = "default", "sleep";
                pinctrl-0 = <&qup_spi3_data_clk>, <&qup_spi3_cs>;

                #address-cells = <1>;
                #size-cells = <0>;

                status = "disabled";
            };

            i2c4: i2c@890000 {
                compatible = "qcom,geni-i2c";
                reg = <0 890000 0 0x4000>;
                interrupts = <GIC_SPI 586 IRQ_TYPE_LEVEL_HIGH 0>;
                clock-names = "se";
                clocks = <&gcc GCC_QUPV3_WRAP0_S4_CLK>;
                interconnects = 
		    	<&clk_virt MASTER_QUP_CORE_0 &clk_virt SLAVE_QUP_CORE_0>,
		    	<&gem_noc MASTER_APPSS_PROC &config_noc SLAVE_QUP_0>,
			    <&aggre2_noc MASTER_QUP_0 &mc_virt  SLAVE_EBI1>;
                interconnect-names = "qup-core", "qup-config", "qup-memory";
                dmas = <&gpi_dma0 0 4 QCOM_GPI_I2C>,
                    <&gpi_dma0 1 4 QCOM_GPI_I2C>;
                dma-names = "tx", "rx";
                pinctrl-0 = <&qup_i2c4_data_clk>;
                pinctrl-names = "default", "sleep";
                #address-cells = <1>;
                #size-cells = <0>;

                status = "disabled";
            };

            spi4: spi@890000 {
                compatible = "qcom,geni-spi";
                reg = <0 890000 0 0x4000>;
                interrupts = <GIC_SPI 586 IRQ_TYPE_LEVEL_HIGH 0>;
                clock-names = "se";
                clocks = <&gcc GCC_QUPV3_WRAP0_S4_CLK>;
                interconnects =
                <&clk_virt MASTER_QUP_CORE_0 &clk_virt SLAVE_QUP_CORE_0>,
                <&gem_noc MASTER_APPSS_PROC &config_noc SLAVE_QUP_0>,
                <&aggre2_noc MASTER_QUP_0 &mc_virt  SLAVE_EBI1>;
                interconnect-names = "qup-core", "qup-config", "qup-memory";
                dmas = <&gpi_dma0 0 4 QCOM_GPI_SPI>,
                    <&gpi_dma0 1 4 QCOM_GPI_SPI>;
                dma-names = "tx", "rx";
                pinctrl-names = "default", "sleep";
                pinctrl-0 = <&qup_spi4_data_clk>, <&qup_spi4_cs>;

                #address-cells = <1>;
                #size-cells = <0>;

                status = "disabled";
            };

            /* Debug UART Instance */
            uart5: qcom,qup_uart@894000 {
                compatible = "qcom,geni-debug-uart";
                reg = <0 0x894000 0 0x4000>;
                interrupts = <GIC_SPI 587 IRQ_TYPE_LEVEL_HIGH 0>;
                
                clocks = <&gcc GCC_QUPV3_WRAP0_S5_CLK>;
                clock-names = "se";

                interconnects =
                <&clk_virt MASTER_QUP_CORE_0 &clk_virt SLAVE_QUP_CORE_0>,
                <&gem_noc MASTER_APPSS_PROC &config_noc SLAVE_QUP_0>,
                <&aggre2_noc MASTER_QUP_0 &mc_virt  SLAVE_EBI1>;
                interconnect-names = "qup-core", "qup-config", "qup-memory";

                pinctrl-0 = <&qup_uart5_default>;
                pinctrl-names = "default", "sleep";

                status = "disabled";
            };

            i2c6: i2c@898000 {
                compatible = "qcom,geni-i2c";
                reg = <0 898000 0 0x4000>;
                interrupts = <GIC_SPI 461 IRQ_TYPE_LEVEL_HIGH 0>;
                clock-names = "se";
                clocks = <&gcc GCC_QUPV3_WRAP0_S6_CLK>;
                interconnects = 
                <&clk_virt MASTER_QUP_CORE_0 &clk_virt SLAVE_QUP_CORE_0>,
                <&gem_noc MASTER_APPSS_PROC &config_noc SLAVE_QUP_0>,
                <&aggre2_noc MASTER_QUP_0 &mc_virt  SLAVE_EBI1>;
                interconnect-names = "qup-core", "qup-config", "qup-memory";
                dmas = <&gpi_dma0 0 6 QCOM_GPI_I2C>,
                    <&gpi_dma0 1 6 QCOM_GPI_I2C>;
                dma-names = "tx", "rx";
                pinctrl-0 = <&qup_i2c6_data_clk>;
                pinctrl-names = "default", "sleep";
                #address-cells = <1>;
                #size-cells = <0>;

                status = "disabled";
            };

            spi6: spi@898000 {
                compatible = "qcom,geni-spi";
                reg = <0 898000 0 0x4000>;
                interrupts = <GIC_SPI 461 IRQ_TYPE_LEVEL_HIGH 0>;
                clock-names = "se";
                clocks = <&gcc GCC_QUPV3_WRAP0_S6_CLK>;
                interconnects =
                <&clk_virt MASTER_QUP_CORE_0 &clk_virt SLAVE_QUP_CORE_0>,
                <&gem_noc MASTER_APPSS_PROC &config_noc SLAVE_QUP_0>,
                <&aggre2_noc MASTER_QUP_0 &mc_virt  SLAVE_EBI1>;
                interconnect-names = "qup-core", "qup-config", "qup-memory";
                dmas = <&gpi_dma0 0 6 QCOM_GPI_SPI>,
                    <&gpi_dma0 1 6 QCOM_GPI_SPI>;
                dma-names = "tx", "rx";
                pinctrl-names = "default", "sleep";
                pinctrl-0 = <&qup_spi6_data_clk>, <&qup_spi6_cs>;

                #address-cells = <1>;
                #size-cells = <0>;

                status = "disabled";
            };

            i2c7: i2c@89c000 {
                compatible = "qcom,geni-i2c";
                reg = <0 89c000 0 0x4000>;
                interrupts = <GIC_SPI 462 IRQ_TYPE_LEVEL_HIGH 0>;
                clock-names = "se";
                clocks = <&gcc GCC_QUPV3_WRAP0_S7_CLK>;
                interconnects = 
                <&clk_virt MASTER_QUP_CORE_0 &clk_virt SLAVE_QUP_CORE_0>,
                <&gem_noc MASTER_APPSS_PROC &config_noc SLAVE_QUP_0>,
                <&aggre2_noc MASTER_QUP_0 &mc_virt  SLAVE_EBI1>;
                interconnect-names = "qup-core", "qup-config", "qup-memory";
                dmas = <&gpi_dma0 0 7 QCOM_GPI_I2C>,
                    <&gpi_dma0 1 7 QCOM_GPI_I2C>;
                dma-names = "tx", "rx";
                pinctrl-0 = <&qup_i2c7_data_clk>;
                pinctrl-names = "default", "sleep";
                #address-cells = <1>;
                #size-cells = <0>;

                status = "disabled";
            };

            spi7: spi@89c000 {
                compatible = "qcom,geni-spi";
                reg = <0 0x89c000 0 0x4000>;
                interrupts = <GIC_SPI 462 IRQ_TYPE_LEVEL_HIGH 0>;
                clock-names = "se";
                clocks = <&gcc GCC_QUPV3_WRAP0_S7_CLK>;
                interconnects =
                <&clk_virt MASTER_QUP_CORE_0 &clk_virt SLAVE_QUP_CORE_0>,
                <&gem_noc MASTER_APPSS_PROC &config_noc SLAVE_QUP_0>,
                <&aggre2_noc MASTER_QUP_0 &mc_virt  SLAVE_EBI1>;
                interconnect-names = "qup-core", "qup-config", "qup-memory";
                dmas = <&gpi_dma0 0 7 QCOM_GPI_SPI>,
                    <&gpi_dma0 1 7 QCOM_GPI_SPI>;
                dma-names = "tx", "rx";
                pinctrl-names = "default", "sleep";
                pinctrl-0 = <&qup_spi7_data_clk>, <&qup_spi7_cs>;

                #address-cells = <1>;
                #size-cells = <0>;

                status = "disabled";
            };
        };

        /* QUPv3_1  wrapper  instance */
        qupv3_id_1: geniqup@ac0000 {
            compatible = "qcom,geni-se-qup";
            reg = <0 0xac0000 0 0x2000>;
			ranges;
            clock-names = "m-ahb", "s-ahb";
            clocks = <&gcc GCC_QUPV3_WRAP_0_M_AHB_CLK>,
                <&gcc GCC_QUPV3_WRAP_0_S_AHB_CLK>;
            iommus = <&apps_smmu 0x23 0x0>;
            dma-coherent;
            #address-cells = <1>;
			#size-cells = <1>;
            status = "ok";

			i2c8: i2c@a80000 {
                compatible = "qcom,geni-i2c";
                reg = <0 0xa80000 0 0x4000>;
                interrupts = <GIC_SPI 353 IRQ_TYPE_LEVEL_HIGH 0>;
                clock-names = "se";
                clocks = <&gcc GCC_QUPV3_WRAP1_S0_CLK>;
                interconnects = 
                <&clk_virt MASTER_QUP_CORE_1 &clk_virt SLAVE_QUP_CORE_1>,
                <&gem_noc MASTER_APPSS_PROC &config_noc SLAVE_QUP_1>,
                <&aggre1_noc MASTER_QUP_1 &mc_virt  SLAVE_EBI1>;
                interconnect-names = "qup-core", "qup-config", "qup-memory";
                dmas = <&gpi_dma1 0 0 QCOM_GPI_I2C>,
                    <&gpi_dma1 1 0 QCOM_GPI_I2C>;
                dma-names = "tx", "rx";
                pinctrl-0 = <&qup_i2c8_data_clk>;
                pinctrl-names = "default", "sleep";
                #address-cells = <1>;
                #size-cells = <0>;

                status = "disabled";
			};

            spi8: spi@a80000 {
                compatible = "qcom,geni-spi";
                reg = <0 0xa80000 0 0x4000>;
                interrupts = <GIC_SPI 353 IRQ_TYPE_LEVEL_HIGH 0>;
                clock-names = "se";
                clocks = <&gcc GCC_QUPV3_WRAP1_S0_CLK>;
                interconnects =
                <&clk_virt MASTER_QUP_CORE_1 &clk_virt SLAVE_QUP_CORE_1>,
                <&gem_noc MASTER_APPSS_PROC &config_noc SLAVE_QUP_1>,
                <&aggre1_noc MASTER_QUP_1 &mc_virt  SLAVE_EBI1>;
                interconnect-names = "qup-core", "qup-config", "qup-memory";
                dmas = <&gpi_dma1 0 0 QCOM_GPI_SPI>,
                    <&gpi_dma1 1 0 QCOM_GPI_SPI>;
                dma-names = "tx", "rx";
                pinctrl-names = "default", "sleep";
                pinctrl-0 = <&qup_spi8_data_clk>, <&qup_spi8_cs>;

                #address-cells = <1>;
                #size-cells = <0>;

                status = "disabled";
            };

			i2c9: i2c@a84000 {
                compatible = "qcom,geni-i2c";
                reg = <0 0xa84000 0 0x4000>;
                interrupts = <GIC_SPI 354 IRQ_TYPE_LEVEL_HIGH 0>;
                clock-names = "se";
                clocks = <&gcc GCC_QUPV3_WRAP1_S1_CLK>;
                interconnects = 
                <&clk_virt MASTER_QUP_CORE_1 &clk_virt SLAVE_QUP_CORE_1>,
                <&gem_noc MASTER_APPSS_PROC &config_noc SLAVE_QUP_1>,
                <&aggre1_noc MASTER_QUP_1 &mc_virt  SLAVE_EBI1>;
                interconnect-names = "qup-core", "qup-config", "qup-memory";
                dmas = <&gpi_dma1 0 1 QCOM_GPI_I2C>,
                    <&gpi_dma1 1 1 QCOM_GPI_I2C>;
                dma-names = "tx", "rx";
                pinctrl-0 = <&qup_i2c9_data_clk>;
                pinctrl-names = "default", "sleep";
                #address-cells = <1>;
                #size-cells = <0>;

                status = "disabled";
			};

            spi9: spi@a84000 {
                compatible = "qcom,geni-spi";
                reg = <0 0xa84000 0 0x4000>;
                interrupts = <GIC_SPI 354 IRQ_TYPE_LEVEL_HIGH 0>;
                clock-names = "se";
                clocks = <&gcc GCC_QUPV3_WRAP1_S1_CLK>;
                interconnects =
                <&clk_virt MASTER_QUP_CORE_1 &clk_virt SLAVE_QUP_CORE_1>,
                <&gem_noc MASTER_APPSS_PROC &config_noc SLAVE_QUP_1>,
                <&aggre1_noc MASTER_QUP_1 &mc_virt  SLAVE_EBI1>;
                interconnect-names = "qup-core", "qup-config", "qup-memory";
                dmas = <&gpi_dma1 0 1 QCOM_GPI_SPI>,
                    <&gpi_dma1 1 1 QCOM_GPI_SPI>;
                dma-names = "tx", "rx";
                pinctrl-names = "default", "sleep";
                pinctrl-0 = <&qup_spi9_data_clk>, <&qup_spi9_cs>;

                #address-cells = <1>;
                #size-cells = <0>;

                status = "disabled";
            };

            /* HS UART Instance */
            uart10: qcom,qup_uart@a88000 {
                compatible = "qcom,geni-uart";
                reg = <0 0xa88000 0 0x4000>;
                interrupts = <GIC_SPI 355 IRQ_TYPE_LEVEL_HIGH 0>;
                
                clocks = <&gcc GCC_QUPV3_WRAP1_S2_CLK>;
                clock-names = "se";

                interconnects =
                <&clk_virt MASTER_QUP_CORE_1 &clk_virt SLAVE_QUP_CORE_1>,
                <&gem_noc MASTER_APPSS_PROC &config_noc SLAVE_QUP_1>,
                <&aggre1_noc MASTER_QUP_1 &mc_virt  SLAVE_EBI1>;
                interconnect-names = "qup-core", "qup-config", "qup-memory";

                pinctrl-0 = <&qup_uart10_default>, <&qup_uart10_cts_rts>;
                pinctrl-names = "default", "sleep";

                status = "disabled";
            };

            i2c11: i2c@a8c000 {
                compatible = "qcom,geni-i2c";
                reg = <0 0xa8c000 0 0x4000>;
                interrupts = <GIC_SPI 356 IRQ_TYPE_LEVEL_HIGH 0>;
                clock-names = "se";
                clocks = <&gcc GCC_QUPV3_WRAP1_S3_CLK>;
                interconnects = 
                <&clk_virt MASTER_QUP_CORE_1 &clk_virt SLAVE_QUP_CORE_1>,
                <&gem_noc MASTER_APPSS_PROC &config_noc SLAVE_QUP_1>,
                <&aggre1_noc MASTER_QUP_1 &mc_virt  SLAVE_EBI1>;
                interconnect-names = "qup-core", "qup-config", "qup-memory";
                dmas = <&gpi_dma1 0 3 QCOM_GPI_I2C>,
                    <&gpi_dma1 1 3 QCOM_GPI_I2C>;
                dma-names = "tx", "rx";
                pinctrl-0 = <&qup_i2c11_data_clk>;
                pinctrl-names = "default", "sleep";
                #address-cells = <1>;
                #size-cells = <0>;

                status = "disabled";
            };

            spi11: spi@a8c000 {
                compatible = "qcom,geni-spi";
                reg = <0 0xa8c000 0 0x4000>;
                interrupts = <GIC_SPI 356 IRQ_TYPE_LEVEL_HIGH 0>;
                clock-names = "se";
                clocks = <&gcc GCC_QUPV3_WRAP1_S3_CLK>;
                interconnects =
                <&clk_virt MASTER_QUP_CORE_1 &clk_virt SLAVE_QUP_CORE_1>,
                <&gem_noc MASTER_APPSS_PROC &config_noc SLAVE_QUP_1>,
                <&aggre1_noc MASTER_QUP_1 &mc_virt  SLAVE_EBI1>;
                interconnect-names = "qup-core", "qup-config", "qup-memory";
                dmas = <&gpi_dma1 0 3 QCOM_GPI_SPI>,
                    <&gpi_dma1 1 3 QCOM_GPI_SPI>;
                dma-names = "tx", "rx";
                pinctrl-names = "default", "sleep";
                pinctrl-0 = <&qup_spi11_data_clk>, <&qup_spi11_cs>;

                #address-cells = <1>;
                #size-cells = <0>;

                status = "disabled";
            };

            i2c12: i2c@a90000 {
                compatible = "qcom,geni-i2c";
                reg = <0 0xa90000 0 0x4000>;
                interrupts = <GIC_SPI 357 IRQ_TYPE_LEVEL_HIGH 0>;
                clock-names = "se";
                clocks = <&gcc GCC_QUPV3_WRAP1_S4_CLK>;
                interconnects = 
                <&clk_virt MASTER_QUP_CORE_1 &clk_virt SLAVE_QUP_CORE_1>,
                <&gem_noc MASTER_APPSS_PROC &config_noc SLAVE_QUP_1>,
                <&aggre1_noc MASTER_QUP_1 &mc_virt  SLAVE_EBI1>;
                interconnect-names = "qup-core", "qup-config", "qup-memory";
                dmas = <&gpi_dma1 0 4 QCOM_GPI_I2C>,
                    <&gpi_dma1 1 4 QCOM_GPI_I2C>;
                dma-names = "tx", "rx";
                pinctrl-0 = <&qup_i2c12_data_clk>;
                pinctrl-names = "default", "sleep";
                #address-cells = <1>;
                #size-cells = <0>;

                status = "disabled";
            };

            spi12: spi@a90000 {
                compatible = "qcom,geni-spi";
                reg = <0 0xa90000 0 0x4000>;
                interrupts = <GIC_SPI 357 IRQ_TYPE_LEVEL_HIGH 0>;
                clock-names = "se";
                clocks = <&gcc GCC_QUPV3_WRAP1_S4_CLK>;
                interconnects =
                <&clk_virt MASTER_QUP_CORE_1 &clk_virt SLAVE_QUP_CORE_1>,
                <&gem_noc MASTER_APPSS_PROC &config_noc SLAVE_QUP_1>,
                <&aggre1_noc MASTER_QUP_1 &mc_virt  SLAVE_EBI1>;
                interconnect-names = "qup-core", "qup-config", "qup-memory";
                dmas = <&gpi_dma1 0 4 QCOM_GPI_SPI>,
                    <&gpi_dma1 1 4 QCOM_GPI_SPI>;
                dma-names = "tx", "rx";
                pinctrl-names = "default", "sleep";
                pinctrl-0 = <&qup_spi12_data_clk>, <&qup_spi12_cs>;

                #address-cells = <1>;
                #size-cells = <0>;

                status = "disabled";
            };

            i2c13: i2c@a94000 {
                compatible = "qcom,geni-i2c";
                reg = <0 0xa94000 0 0x4000>;
                interrupts = <GIC_SPI 358 IRQ_TYPE_LEVEL_HIGH 0>;
                clock-names = "se";
                clocks = <&gcc GCC_QUPV3_WRAP1_S5_CLK>;
                interconnects = 
                <&clk_virt MASTER_QUP_CORE_1 &clk_virt SLAVE_QUP_CORE_1>,
                <&gem_noc MASTER_APPSS_PROC &config_noc SLAVE_QUP_1>,
                <&aggre1_noc MASTER_QUP_1 &mc_virt  SLAVE_EBI1>;
                interconnect-names = "qup-core", "qup-config", "qup-memory";
                dmas = <&gpi_dma1 0 5 QCOM_GPI_I2C>,
                    <&gpi_dma1 1 5 QCOM_GPI_I2C>;
                dma-names = "tx", "rx";
                pinctrl-0 = <&qup_i2c13_data_clk>;
                pinctrl-names = "default", "sleep";
                #address-cells = <1>;
                #size-cells = <0>;

                status = "disabled";
            };

            spi13: spi@a94000 {
                compatible = "qcom,geni-spi";
                reg = <0 0xa94000 0 0x4000>;
                interrupts = <GIC_SPI 358 IRQ_TYPE_LEVEL_HIGH 0>;
                clock-names = "se";
                clocks = <&gcc GCC_QUPV3_WRAP1_S5_CLK>;
                interconnects =
                <&clk_virt MASTER_QUP_CORE_1 &clk_virt SLAVE_QUP_CORE_1>,
                <&gem_noc MASTER_APPSS_PROC &config_noc SLAVE_QUP_1>,
                <&aggre1_noc MASTER_QUP_1 &mc_virt  SLAVE_EBI1>;
                interconnect-names = "qup-core", "qup-config", "qup-memory";
                dmas = <&gpi_dma1 0 6 QCOM_GPI_SPI>,
                    <&gpi_dma1 1 6 QCOM_GPI_SPI>;
                dma-names = "tx", "rx";
                pinctrl-names = "default", "sleep";
                pinctrl-0 = <&qup_spi13_data_clk>, <&qup_spi13_cs>;

                #address-cells = <1>;
                #size-cells = <0>;

                status = "disabled";
            };

            i2c14: i2c@a98000 {
                compatible = "qcom,geni-i2c";
                reg = <0 0xa98000 0 0x4000>;
                interrupts = <GIC_SPI 363 IRQ_TYPE_LEVEL_HIGH 0>;
                clock-names = "se";
                clocks = <&gcc GCC_QUPV3_WRAP1_S6_CLK>;
                interconnects = 
                <&clk_virt MASTER_QUP_CORE_1 &clk_virt SLAVE_QUP_CORE_1>,
                <&gem_noc MASTER_APPSS_PROC &config_noc SLAVE_QUP_1>,
                <&aggre1_noc MASTER_QUP_1 &mc_virt  SLAVE_EBI1>;
                interconnect-names = "qup-core", "qup-config", "qup-memory";
                dmas = <&gpi_dma1 0 6 QCOM_GPI_I2C>,
                    <&gpi_dma1 1 6 QCOM_GPI_I2C>;
                dma-names = "tx", "rx";
                pinctrl-0 = <&qup_i2c14_data_clk>;
                pinctrl-names = "default", "sleep";
                #address-cells = <1>;
                #size-cells = <0>;

                status = "disabled";
            };

            spi14: spi@a98000 {
                compatible = "qcom,geni-spi";
                reg = <0 0xa98000 0 0x4000>;
                interrupts = <GIC_SPI 363 IRQ_TYPE_LEVEL_HIGH 0>;
                clock-names = "se";
                clocks = <&gcc GCC_QUPV3_WRAP1_S6_CLK>;
                interconnects =
                <&clk_virt MASTER_QUP_CORE_1 &clk_virt SLAVE_QUP_CORE_1>,
                <&gem_noc MASTER_APPSS_PROC &config_noc SLAVE_QUP_1>,
                <&aggre1_noc MASTER_QUP_1 &mc_virt  SLAVE_EBI1>;
                interconnect-names = "qup-core", "qup-config", "qup-memory";
                dmas = <&gpi_dma1 0 6 QCOM_GPI_SPI>,
                    <&gpi_dma1 1 6 QCOM_GPI_SPI>;
                dma-names = "tx", "rx";
                pinctrl-names = "default", "sleep";
                pinctrl-0 = <&qup_spi14_data_clk>, <&qup_spi14_cs>;

                #address-cells = <1>;
                #size-cells = <0>;

                status = "disabled";
            };

            i2c15: i2c@a9C000 {
                compatible = "qcom,geni-i2c";
                reg = <0 0xa9C000 0 0x4000>;
                interrupts = <GIC_SPI 371 IRQ_TYPE_LEVEL_HIGH 0>;
                clock-names = "se";
                clocks = <&gcc GCC_QUPV3_WRAP1_S7_CLK>;
                interconnects = 
                <&clk_virt MASTER_QUP_CORE_1 &clk_virt SLAVE_QUP_CORE_1>,
                <&gem_noc MASTER_APPSS_PROC &config_noc SLAVE_QUP_1>,
                <&aggre1_noc MASTER_QUP_1 &mc_virt  SLAVE_EBI1>;
                interconnect-names = "qup-core", "qup-config", "qup-memory";
                dmas = <&gpi_dma1 0 7 QCOM_GPI_I2C>,
                    <&gpi_dma1 1 7 QCOM_GPI_I2C>;
                dma-names = "tx", "rx";
                pinctrl-0 = <&qup_i2c15_data_clk>;
                pinctrl-names = "default", "sleep";
                #address-cells = <1>;
                #size-cells = <0>;

                status = "disabled";
            };

            spi15: spi@a9C000 {
                compatible = "qcom,geni-spi";
                reg = <0 0xa9C000 0 0x4000>;
                interrupts = <GIC_SPI 371 IRQ_TYPE_LEVEL_HIGH 0>;
                clock-names = "se";
                clocks = <&gcc GCC_QUPV3_WRAP1_S7_CLK>;
                interconnects =
                <&clk_virt MASTER_QUP_CORE_1 &clk_virt SLAVE_QUP_CORE_1>,
                <&gem_noc MASTER_APPSS_PROC &config_noc SLAVE_QUP_1>,
                <&aggre1_noc MASTER_QUP_1 &mc_virt  SLAVE_EBI1>;
                interconnect-names = "qup-core", "qup-config", "qup-memory";
                dmas = <&gpi_dma1 0 7 QCOM_GPI_SPI>,
                    <&gpi_dma1 1 7 QCOM_GPI_SPI>;
                dma-names = "tx", "rx";
                pinctrl-names = "default", "sleep";
                pinctrl-0 = <&qup_spi15_data_clk>, <&qup_spi15_cs>;

                #address-cells = <1>;
                #size-cells = <0>;

                status = "disabled";
            };
        };

        cnoc_main: interconnect@1500000 {
            compatible = "qcom,sm7550-cnoc-main";
            reg = <0x1500000 0x13080>;
            #interconnect-cells = <1>;
            qcom,bcm-voters = <&apps_bcm_voter>;
        };

    	config_noc: interconnect@1600000 {
            compatible = "qcom,sm7550-config-noc";
            reg = <0x01600000 0x9080>;
            #interconnect-cells = <1>;
            qcom,bcm-voters = <&apps_bcm_voter>;
        };

        system_noc: interconnect@1680000 {
            compatible = "qcom,sm7550-system-noc";
            reg = <0x01680000 0x1D080>;
            #interconnect-cells = <1>;
            qcom,bcm-voters = <&apps_bcm_voter>;
        };

        pcie_noc: interconnect@16c0000 {
            compatible = "qcom,sm7550-pcie-noc";
            reg = <0x016C0000 0x12200>;
            #interconnect-cells = <1>;
            clocks = <&gcc GCC_AGGRE_NOC_PCIE_AXI_CLK>,
                <&gcc GCC_CFG_NOC_PCIE_ANOC_AHB_CLK>;
            qcom,bcm-voter-names = "hlos";
            qcom,bcm-voters = <&apps_bcm_voter>;
        };

        aggre1_noc: interconnect@16e0000 {
            compatible = "qcom,sm7550-aggre1-noc";
            reg = <0x016E0000 0x14400>;
            #interconnect-cells = <1>;
            clocks =
                <&gcc GCC_AGGRE_UFS_PHY_AXI_CLK>,
                <&gcc GCC_AGGRE_USB3_PRIM_AXI_CLK>;
            qcom,bcm-voter-names = "hlos";
            qcom,bcm-voters = <&apps_bcm_voter>;
        };

        aggre2_noc: interconnect@1700000 {
            compatible = "qcom,sm7550-aggre2-noc";
            reg = <0x01700000 0x1F400>;
            #interconnect-cells = <1>;
            clocks = <&rpmhcc RPMH_IPA_CLK>;
            qcom,bcm-voter-names = "hlos";
            qcom,bcm-voters = <&apps_bcm_voter>;
        };

        mmss_noc: interconnect@1780000 {
            compatible = "qcom,sm7550-mmss-noc";
            reg = <0x01780000 0x5b800>;
            #interconnect-cells = <1>;
            qcom,bcm-voter-names = "hlos", "disp";
            qcom,bcm-voters = <&apps_bcm_voter>, <&disp_bcm_voter>;
        };

        gem_noc: interconnect@24100000 {
            compatible = "qcom,sm7550-gem-noc";
            reg = <0x24100000 0xBD080>;
            #interconnect-cells = <1>;
            qcom,bcm-voter-names = "hlos", "disp";
            qcom,bcm-voters = <&apps_bcm_voter>, <&disp_bcm_voter>;
        };

        nsp_noc: interconnect@320c0000 {
            compatible = "qcom,sm7550-nsp-noc";
            reg = <0x320C0000 0xE080>;
            #interconnect-cells = <1>;
            qcom,bcm-voter-names = "hlos";
            qcom,bcm-voters = <&apps_bcm_voter>;
        };

        lpass_ag_noc: interconnect@3C40000 {
            compatible = "qcom,sm7550-lpass-ag-noc";
            reg = <0x03C40000 0x17200>;
            #interconnect-cells = <1>;
            qcom,bcm-voter-names = "hlos";
            qcom,bcm-voters = <&apps_bcm_voter>;
        };

		rng: rng@10c3000 {
			compatible = "qcom,sm7550-trng", "qcom,trng";
			reg = <0 0x010c3000 0 0x1000>;
		};

        ufs_mem_phy: phy@1d80000 {
            compatible = "qcom,sm7550-qmp-ufs-phy";
            reg = <0 0x1d80000 0 0x2000>;
            reg-names = "phy_mem";

            lanes-per-direction = <2>;
			clock-names = "ref",
				      "ref_aux",
				      "qref";
            clocks = <&rpmhcc RPMH_CXO_CLK>,
                <&gcc GCC_UFS_PHY_PHY_AUX_CLK>,
                <&tcsrcc TCSR_UFS_CLKREF_EN>;
            resets = <&ufs_mem_hc 0>;
			reset-names = "ufsphy";

            #phy-cells = <0>;

            status = "disabled";
        };

		ufs_mem_hc: ufshc@1d84000 {
			compatible = "qcom,sm7550-ufshc", "qcom,ufshc", "jedec,ufs-2.0";
			reg = <0x0 0x1d84000 0x0 0x3000>;

			interrupts = <GIC_SPI 265 IRQ_TYPE_LEVEL_HIGH 0>;

			clocks = <&gcc GCC_UFS_PHY_AXI_CLK>,
				 <&gcc GCC_AGGRE_UFS_PHY_AXI_CLK>,
				 <&gcc GCC_UFS_PHY_AHB_CLK>,
				 <&gcc GCC_UFS_PHY_UNIPRO_CORE_CLK>,
				 <&tcsr TCSR_UFS_PAD_CLKREF_EN>,
				 <&gcc GCC_UFS_PHY_TX_SYMBOL_0_CLK>,
				 <&gcc GCC_UFS_PHY_RX_SYMBOL_0_CLK>,
				 <&gcc GCC_UFS_PHY_RX_SYMBOL_1_CLK>;
			clock-names = "core_clk",
				      "bus_aggr_clk",
				      "iface_clk",
				      "core_clk_unipro",
				      "ref_clk",
				      "tx_lane0_sync_clk",
				      "rx_lane0_sync_clk",
				      "rx_lane1_sync_clk";

			resets = <&gcc GCC_UFS_PHY_BCR>;
			reset-names = "rst";

			interconnects = <&aggre1_noc MASTER_UFS_MEM QCOM_ICC_TAG_ALWAYS
					 &mc_virt SLAVE_EBI1 QCOM_ICC_TAG_ALWAYS>,
					<&gem_noc MASTER_APPSS_PROC QCOM_ICC_TAG_ACTIVE_ONLY
					 &cnoc_cfg SLAVE_UFS_MEM_CFG QCOM_ICC_TAG_ACTIVE_ONLY>;
			interconnect-names = "ufs-ddr",
					     "cpu-ufs";

			power-domains = <&gcc UFS_PHY_GDSC>;
			required-opps = <&rpmhpd_opp_nom>;

			operating-points-v2 = <&ufs_opp_table>;

			iommus = <&apps_smmu 0x20 0>;

			dma-coherent;

			lanes-per-direction = <2>;
			qcom,ice = <&ice>;

			phys = <&ufs_mem_phy>;
			phy-names = "ufsphy";

			#reset-cells = <1>;

			status = "disabled";

			ufs_opp_table: opp-table {
				compatible = "operating-points-v2";

				opp-75000000 {
					opp-hz = /bits/ 64 <75000000>,
						 /bits/ 64 <0>,
						 /bits/ 64 <0>,
						 /bits/ 64 <75000000>,
						 /bits/ 64 <0>,
						 /bits/ 64 <0>,
						 /bits/ 64 <0>,
						 /bits/ 64 <0>;
					required-opps = <&rpmhpd_opp_low_svs>;
				};

				opp-150000000 {
					opp-hz = /bits/ 64 <150000000>,
						 /bits/ 64 <0>,
						 /bits/ 64 <0>,
						 /bits/ 64 <150000000>,
						 /bits/ 64 <0>,
						 /bits/ 64 <0>,
						 /bits/ 64 <0>,
						 /bits/ 64 <0>;
					required-opps = <&rpmhpd_opp_svs>;
				};

				opp-300000000 {
					opp-hz = /bits/ 64 <300000000>,
						 /bits/ 64 <0>,
						 /bits/ 64 <0>,
						 /bits/ 64 <300000000>,
						 /bits/ 64 <0>,
						 /bits/ 64 <0>,
						 /bits/ 64 <0>,
						 /bits/ 64 <0>;
					required-opps = <&rpmhpd_opp_nom>;
				};
			};
		};

		ice: crypto@1d88000 {
			compatible = "qcom,milos-inline-crypto-engine",
				     "qcom,inline-crypto-engine";
			reg = <0x0 0x01d88000 0x0 0x18000>;

			clocks = <&gcc GCC_UFS_PHY_ICE_CORE_CLK>,
				 <&gcc GCC_UFS_PHY_AHB_CLK>;
			clock-names = "core",
				      "iface";
			power-domains = <&gcc UFS_PHY_GDSC>;
		};

        tcsr_mutex: hwlock {
            compatible = "qcom,tcsr-mutex";
            syscon = <0 0x1f40000 0 0x20000>;
            #hwlock-cells = <1>;
        };

        tcsr: clock-controller@1fc0000 {
			compatible = "qcom,sm7550-tcsr", "syscon";
			reg = <0 0x01fc0000 0 0x30000>;
			clocks = <&rpmhcc RPMH_CXO_CLK>;
			#clock-cells = <1>;
			#reset-cells = <1>;
		};

        gpucc: clock-controller@3d90000 {
            compatible = "qcom,sm7550-gpucc";
            reg = <0 0x3d90000 0 0xa000>;
            clocks = <&rpmhcc RPMH_CXO_CLK>,
                <&rpmhcc RPMH_CXO_CLK_A>,
                <&gcc GCC_GPU_GPLL0_CLK_SRC>,
                <&gcc GCC_GPU_GPLL0_DIV_CLK_SRC>;
            #clock-cells = <1>;
            #reset-cells = <1>;
			#power-domain-cells = <1>;
        };

		adreno_smmu: iommu@3da0000 {
			compatible = "qcom,sm7550-smmu-500", "qcom,adreno-smmu",
				     "qcom,smmu-500", "arm,mmu-500";
			reg = <0x0 0x03da0000 0x0 0x40000>;
			#iommu-cells = <2>;
			#global-interrupts = <1>;
			interrupts = <GIC_SPI 673 IRQ_TYPE_LEVEL_HIGH 0>,
				     <GIC_SPI 677 IRQ_TYPE_LEVEL_HIGH 0>,
				     <GIC_SPI 678 IRQ_TYPE_LEVEL_HIGH 0>,
				     <GIC_SPI 679 IRQ_TYPE_LEVEL_HIGH 0>,
				     <GIC_SPI 680 IRQ_TYPE_LEVEL_HIGH 0>,
				     <GIC_SPI 681 IRQ_TYPE_LEVEL_HIGH 0>,
				     <GIC_SPI 682 IRQ_TYPE_LEVEL_HIGH 0>,
				     <GIC_SPI 683 IRQ_TYPE_LEVEL_HIGH 0>,
				     <GIC_SPI 684 IRQ_TYPE_LEVEL_HIGH 0>,
				     <GIC_SPI 685 IRQ_TYPE_LEVEL_HIGH 0>,
				     <GIC_SPI 686 IRQ_TYPE_LEVEL_HIGH 0>,
				     <GIC_SPI 687 IRQ_TYPE_LEVEL_HIGH 0>,
				     <GIC_SPI 422 IRQ_TYPE_LEVEL_HIGH 0>,
				     <GIC_SPI 476 IRQ_TYPE_LEVEL_HIGH 0>,
				     <GIC_SPI 574 IRQ_TYPE_LEVEL_HIGH 0>,
				     <GIC_SPI 575 IRQ_TYPE_LEVEL_HIGH 0>,
				     <GIC_SPI 576 IRQ_TYPE_LEVEL_HIGH 0>,
				     <GIC_SPI 577 IRQ_TYPE_LEVEL_HIGH 0>,
				     <GIC_SPI 659 IRQ_TYPE_LEVEL_HIGH 0>,
				     <GIC_SPI 661 IRQ_TYPE_LEVEL_HIGH 0>,
				     <GIC_SPI 664 IRQ_TYPE_LEVEL_HIGH 0>,
				     <GIC_SPI 665 IRQ_TYPE_LEVEL_HIGH 0>,
				     <GIC_SPI 666 IRQ_TYPE_LEVEL_HIGH 0>,
				     <GIC_SPI 668 IRQ_TYPE_LEVEL_HIGH 0>,
				     <GIC_SPI 669 IRQ_TYPE_LEVEL_HIGH 0>,
				     <GIC_SPI 699 IRQ_TYPE_LEVEL_HIGH 0>;
			clocks = <&gpucc GPU_CC_HLOS1_VOTE_GPU_SMMU_CLK>,
				 <&gcc GCC_GPU_MEMNOC_GFX_CLK>,
				 <&gcc GCC_GPU_SNOC_DVM_GFX_CLK>,
				 <&gpucc GPU_CC_AHB_CLK>;
			clock-names = "hlos",
				      "bus",
				      "iface",
				      "ahb";
			power-domains = <&gpucc GPU_CC_CX_GDSC>;
			dma-coherent;
		};


		remoteproc_mpss: remoteproc@4080000 {
			compatible = "qcom,sm7550-mpss-pas";
			reg = <0x0 0x04080000 0x0 0x10000>;

			interrupts-extended = <&intc GIC_SPI 264 IRQ_TYPE_EDGE_RISING 0>,
					      <&smp2p_modem_in 0 IRQ_TYPE_EDGE_RISING>,
					      <&smp2p_modem_in 1 IRQ_TYPE_EDGE_RISING>,
					      <&smp2p_modem_in 2 IRQ_TYPE_EDGE_RISING>,
					      <&smp2p_modem_in 3 IRQ_TYPE_EDGE_RISING>,
					      <&smp2p_modem_in 7 IRQ_TYPE_EDGE_RISING>;
			interrupt-names = "wdog", "fatal", "ready", "handover",
					  "stop-ack", "shutdown-ack";

			clocks = <&rpmhcc RPMH_CXO_CLK>;
			clock-names = "xo";

			power-domains = <&rpmhpd RPMHPD_CX>,
					<&rpmhpd RPMHPD_MSS>;
			power-domain-names = "cx", "mss";

			interconnects = <&mc_virt MASTER_LLCC QCOM_ICC_TAG_ALWAYS
					 &mc_virt SLAVE_EBI1 QCOM_ICC_TAG_ALWAYS>;

			memory-region = <&mpss_mem>, <&q6_mpss_dtb_mem>;

			qcom,qmp = <&aoss_qmp>;

			qcom,smem-states = <&smp2p_modem_out 0>;
			qcom,smem-state-names = "stop";

			status = "disabled";

			glink-edge {
				interrupts-extended = <&ipcc IPCC_CLIENT_MPSS
							     IPCC_MPROC_SIGNAL_GLINK_QMP
							     IRQ_TYPE_EDGE_RISING>;
				mboxes = <&ipcc IPCC_CLIENT_MPSS
						IPCC_MPROC_SIGNAL_GLINK_QMP>;
				label = "mpss";
				qcom,remote-pid = <1>;
			};
		};


		remoteproc_adsp: remoteproc@3000000 {
			compatible = "qcom,sm7550-adsp-pas";
			reg = <0x0 0x03000000 0x0 0x10000>;

			interrupts-extended = <&pdc 6 IRQ_TYPE_EDGE_RISING>,
					      <&smp2p_adsp_in 0 IRQ_TYPE_EDGE_RISING>,
					      <&smp2p_adsp_in 1 IRQ_TYPE_EDGE_RISING>,
					      <&smp2p_adsp_in 2 IRQ_TYPE_EDGE_RISING>,
					      <&smp2p_adsp_in 3 IRQ_TYPE_EDGE_RISING>,
					      <&smp2p_adsp_in 7 IRQ_TYPE_EDGE_RISING>;
			interrupt-names = "wdog",
					  "fatal",
					  "ready",
					  "handover",
					  "stop-ack",
					  "shutdown-ack";

			clocks = <&rpmhcc RPMH_CXO_CLK>;
			clock-names = "xo";

			power-domains = <&rpmhpd RPMHPD_LCX>,
					<&rpmhpd RPMHPD_LMX>;
			power-domain-names = "lcx",
					     "lmx";

			interconnects = <&lpass_ag_noc MASTER_LPASS_PROC QCOM_ICC_TAG_ALWAYS
					 &mc_virt SLAVE_EBI1 QCOM_ICC_TAG_ALWAYS>;

			memory-region = <&adspslpi_mem>, <&q6_adsp_dtb_mem>;

			qcom,qmp = <&aoss_qmp>;

			qcom,smem-states = <&smp2p_adsp_out 0>;
			qcom,smem-state-names = "stop";

			status = "disabled";

			glink-edge {
				interrupts-extended = <&ipcc IPCC_CLIENT_LPASS
							     IPCC_MPROC_SIGNAL_GLINK_QMP
							     IRQ_TYPE_EDGE_RISING>;
				mboxes = <&ipcc IPCC_CLIENT_LPASS
						IPCC_MPROC_SIGNAL_GLINK_QMP>;

				label = "lpass";
				qcom,remote-pid = <2>;

				fastrpc {
					compatible = "qcom,fastrpc";
					qcom,glink-channels = "fastrpcglink-apps-dsp";
					label = "adsp";
					qcom,non-secure-domain;
					#address-cells = <1>;
					#size-cells = <0>;

					compute-cb@10 {
						compatible = "qcom,fastrpc-compute-cb";
						reg = <10>;
                        iommus = <&apps_smmu 0x1002 0x0000>,
                            <&apps_smmu 0x1062 0x0000>;
						dma-coherent;
					};

					compute-cb@11 {
						compatible = "qcom,fastrpc-compute-cb";
						reg = <11>;
                        iommus = <&apps_smmu 0x1003 0x0000>,
                            <&apps_smmu 0x1063 0x0000>;
						dma-coherent;
					};

					compute-cb@12 {
						compatible = "qcom,fastrpc-compute-cb";
						reg = <12>;
                        iommus = <&apps_smmu 0x1004 0x0000>,
                            <&apps_smmu 0x1064 0x0000>;
						dma-coherent;
					};

					compute-cb@13 {
						compatible = "qcom,fastrpc-compute-cb";
						reg = <13>;
                        iommus = <&apps_smmu 0x1005 0x0000>,
                            <&apps_smmu 0x1065 0x0000>;
						dma-coherent;
					};
				};

				gpr {
					compatible = "qcom,gpr";
					qcom,glink-channels = "adsp_apps";
					qcom,domain = <GPR_DOMAIN_ID_ADSP>;
					qcom,intents = <512 20>;
					#address-cells = <1>;
					#size-cells = <0>;

					q6apm: service@1 {
						compatible = "qcom,q6apm";
						reg = <GPR_APM_MODULE_IID>;
						#sound-dai-cells = <0>;
						qcom,protection-domain = "avs/audio",
									 "msm/adsp/audio_pd";

						q6apmbedai: bedais {
							compatible = "qcom,q6apm-lpass-dais";
							#sound-dai-cells = <1>;
						};

						q6apmdai: dais {
							compatible = "qcom,q6apm-dais";
							iommus = <&apps_smmu 0x1001 0x0>,
								 <&apps_smmu 0x1061 0x0>;
						};
					};

					q6prm: service@2 {
						compatible = "qcom,q6prm";
						reg = <GPR_PRM_MODULE_IID>;
						qcom,protection-domain = "avs/audio",
									 "msm/adsp/audio_pd";

						q6prmcc: clock-controller {
							compatible = "qcom,q6prm-lpass-clocks";
							#clock-cells = <2>;
						};
					};
				};
			};
		};

		lpass_wsa2macro: codec@31b0000 {
			compatible = "qcom,sm8450-lpass-wsa-macro";
			reg = <0 0x031b0000 0 0x1000>;
			clocks = <&q6prmcc LPASS_CLK_ID_WSA2_CORE_TX_MCLK LPASS_CLK_ATTRIBUTE_COUPLE_NO>,
				 <&q6prmcc LPASS_CLK_ID_WSA2_CORE_TX_2X_MCLK LPASS_CLK_ATTRIBUTE_COUPLE_NO>,
				 <&q6prmcc LPASS_HW_MACRO_VOTE LPASS_CLK_ATTRIBUTE_COUPLE_NO>,
				 <&q6prmcc LPASS_HW_DCODEC_VOTE LPASS_CLK_ATTRIBUTE_COUPLE_NO>,
				 <&lpass_vamacro>;
			clock-names = "mclk", "npl", "macro", "dcodec", "fsgen";

			#clock-cells = <0>;
			clock-output-names = "wsa2-mclk";
			#sound-dai-cells = <1>;
		};

		swr3: soundwire@31f0000 {
			compatible = "qcom,soundwire-v1.7.0";
			reg = <0 0x031f0000 0 0x2000>;
			interrupts = <GIC_SPI 171 IRQ_TYPE_LEVEL_HIGH 0>;
			clocks = <&lpass_wsa2macro>;
			clock-names = "iface";
			label = "WSA2";

			pinctrl-0 = <&wsa2_swr_active>;
			pinctrl-names = "default";

			qcom,din-ports = <4>;
			qcom,dout-ports = <9>;

			qcom,ports-sinterval =		/bits/ 16 <0x07 0x1f 0x3f 0x07 0x1f 0x3f 0x18f 0xff 0xff 0x0f 0x0f 0xff 0x31f>;
			qcom,ports-offset1 =		/bits/ 8 <0x01 0x03 0x05 0x02 0x04 0x15 0x00 0xff 0xff 0x06 0x0d 0xff 0x00>;
			qcom,ports-offset2 =		/bits/ 8 <0xff 0x07 0x1f 0xff 0x07 0x1f 0xff 0xff 0xff 0xff 0xff 0xff 0xff>;
			qcom,ports-hstart =		/bits/ 8 <0xff 0xff 0xff 0xff 0xff 0xff 0x08 0xff 0xff 0xff 0xff 0xff 0x0f>;
			qcom,ports-hstop =		/bits/ 8 <0xff 0xff 0xff 0xff 0xff 0xff 0x08 0xff 0xff 0xff 0xff 0xff 0x0f>;
			qcom,ports-word-length =	/bits/ 8 <0xff 0xff 0xff 0xff 0xff 0xff 0x08 0xff 0xff 0xff 0xff 0xff 0x18>;
			qcom,ports-block-pack-mode =	/bits/ 8 <0x00 0x01 0x01 0x00 0x01 0x01 0x00 0x00 0x00 0x01 0x01 0x00 0x00>;
			qcom,ports-block-group-count =	/bits/ 8 <0xff 0xff 0xff 0xff 0xff 0xff 0xff 0xff 0xff 0xff 0xff 0xff 0xff>;
			qcom,ports-lane-control =	/bits/ 8 <0xff 0xff 0xff 0xff 0xff 0xff 0xff 0xff 0xff 0xff 0xff 0xff 0xff>;

			#address-cells = <2>;
			#size-cells = <0>;
			#sound-dai-cells = <1>;
			status = "disabled";
		};

		lpass_rxmacro: codec@3200000 {
			compatible = "qcom,sm8450-lpass-rx-macro";
			reg = <0 0x03200000 0 0x1000>;
			clocks = <&q6prmcc LPASS_CLK_ID_RX_CORE_TX_MCLK LPASS_CLK_ATTRIBUTE_COUPLE_NO>,
				 <&q6prmcc LPASS_CLK_ID_RX_CORE_MCLK2_2X_MCLK LPASS_CLK_ATTRIBUTE_COUPLE_NO>,
				 <&q6prmcc LPASS_HW_MACRO_VOTE LPASS_CLK_ATTRIBUTE_COUPLE_NO>,
				 <&q6prmcc LPASS_HW_DCODEC_VOTE LPASS_CLK_ATTRIBUTE_COUPLE_NO>,
				 <&lpass_vamacro>;
			clock-names = "mclk", "npl", "macro", "dcodec", "fsgen";

			#clock-cells = <0>;
			clock-output-names = "mclk";
			#sound-dai-cells = <1>;
		};

		swr1: soundwire@3210000 {
			compatible = "qcom,soundwire-v1.7.0";
			reg = <0 0x03210000 0 0x2000>;
			interrupts = <GIC_SPI 155 IRQ_TYPE_LEVEL_HIGH 0>;
			clocks = <&lpass_rxmacro>;
			clock-names = "iface";
			label = "RX";

			pinctrl-0 = <&rx_swr_active>;
			pinctrl-names = "default";

			qcom,din-ports = <1>;
			qcom,dout-ports = <5>;

			qcom,ports-sinterval =		/bits/ 16 <0x03 0x3f 0x1f 0x07 0x00 0x18f>;
			qcom,ports-offset1 =		/bits/ 8 <0x00 0x00 0x0b 0x01 0x00 0x00>;
			qcom,ports-offset2 =		/bits/ 8 <0x00 0x00 0x0b 0x00 0x00 0x00>;
			qcom,ports-hstart =		/bits/ 8 <0xff 0x03 0xff 0xff 0xff 0x08>;
			qcom,ports-hstop =		/bits/ 8 <0xff 0x06 0xff 0xff 0xff 0x08>;
			qcom,ports-word-length =	/bits/ 8 <0x01 0x07 0x04 0xff 0xff 0x0f>;
			qcom,ports-block-pack-mode =	/bits/ 8 <0xff 0x00 0x01 0xff 0xff 0x00>;
			qcom,ports-block-group-count =	/bits/ 8 <0xff 0xff 0xff 0xff 0x00 0x00>;
			qcom,ports-lane-control =	/bits/ 8 <0x01 0x00 0x00 0x00 0x00 0x00>;

			#address-cells = <2>;
			#size-cells = <0>;
			#sound-dai-cells = <1>;
			status = "disabled";
		};

		lpass_txmacro: codec@3220000 {
			compatible = "qcom,sm8450-lpass-tx-macro";
			reg = <0 0x03220000 0 0x1000>;
			clocks = <&q6prmcc LPASS_CLK_ID_RX_CORE_TX_MCLK LPASS_CLK_ATTRIBUTE_COUPLE_NO>,
				 <&q6prmcc LPASS_CLK_ID_RX_CORE_MCLK2_2X_MCLK LPASS_CLK_ATTRIBUTE_COUPLE_NO>,
				 <&q6prmcc LPASS_HW_MACRO_VOTE LPASS_CLK_ATTRIBUTE_COUPLE_NO>,
				 <&q6prmcc LPASS_HW_DCODEC_VOTE LPASS_CLK_ATTRIBUTE_COUPLE_NO>,
				 <&lpass_vamacro>;
			clock-names = "mclk", "npl", "macro", "dcodec", "fsgen";

			#clock-cells = <0>;
			clock-output-names = "mclk";
			#sound-dai-cells = <1>;
		};

		lpass_wsamacro: codec@3240000 {
			compatible = "qcom,sm8450-lpass-wsa-macro";
			reg = <0 0x03240000 0 0x1000>;
			clocks = <&q6prmcc LPASS_CLK_ID_WSA_CORE_TX_MCLK LPASS_CLK_ATTRIBUTE_COUPLE_NO>,
				 <&q6prmcc LPASS_CLK_ID_WSA_CORE_TX_2X_MCLK LPASS_CLK_ATTRIBUTE_COUPLE_NO>,
				 <&q6prmcc LPASS_HW_MACRO_VOTE LPASS_CLK_ATTRIBUTE_COUPLE_NO>,
				 <&q6prmcc LPASS_HW_DCODEC_VOTE LPASS_CLK_ATTRIBUTE_COUPLE_NO>,
				 <&lpass_vamacro>;
			clock-names = "mclk", "npl", "macro", "dcodec", "fsgen";

			#clock-cells = <0>;
			clock-output-names = "mclk";
			#sound-dai-cells = <1>;
		};

		swr0: soundwire@3250000 {
			compatible = "qcom,soundwire-v1.7.0";
			reg = <0 0x03250000 0 0x2000>;
			interrupts = <GIC_SPI 170 IRQ_TYPE_LEVEL_HIGH 0>;
			clocks = <&lpass_wsamacro>;
			clock-names = "iface";
			label = "WSA";

			pinctrl-0 = <&wsa_swr_active>;
			pinctrl-names = "default";

			qcom,din-ports = <2>;
			qcom,dout-ports = <6>;

			qcom,ports-sinterval-low =	/bits/ 8 <0x07 0x1f 0x3f 0x07 0x1f 0x3f 0x0f 0x0f>;
			qcom,ports-offset1 =		/bits/ 8 <0x01 0x02 0x0c 0x06 0x12 0x0d 0x07 0x0a>;
			qcom,ports-offset2 =		/bits/ 8 <0xff 0x00 0x1f 0xff 0x00 0x1f 0x00 0x00>;
			qcom,ports-hstart =		/bits/ 8 <0xff 0xff 0xff 0xff 0xff 0xff 0xff 0xff>;
			qcom,ports-hstop =		/bits/ 8 <0xff 0xff 0xff 0xff 0xff 0xff 0xff 0xff>;
			qcom,ports-word-length =	/bits/ 8 <0xff 0xff 0xff 0xff 0xff 0xff 0xff 0xff>;
			qcom,ports-block-pack-mode =	/bits/ 8 <0xff 0xff 0x01 0xff 0xff 0x01 0xff 0xff>;
			qcom,ports-block-group-count =	/bits/ 8 <0xff 0xff 0xff 0xff 0xff 0xff 0xff 0xff>;
			qcom,ports-lane-control =	/bits/ 8 <0xff 0xff 0xff 0xff 0xff 0xff 0xff 0xff>;

			#address-cells = <2>;
			#size-cells = <0>;
			#sound-dai-cells = <1>;
			status = "disabled";
		};

		swr2: soundwire@33b0000 {
			compatible = "qcom,soundwire-v1.7.0";
			reg = <0 0x033b0000 0 0x2000>;
			interrupts = <GIC_SPI 496 IRQ_TYPE_LEVEL_HIGH 0>,
				     <GIC_SPI 520 IRQ_TYPE_LEVEL_HIGH 0>;
			interrupt-names = "core", "wakeup";
			clocks = <&lpass_txmacro>;
			clock-names = "iface";
			label = "TX";

			pinctrl-0 = <&tx_swr_active>;
			pinctrl-names = "default";

			qcom,din-ports = <4>;
			qcom,dout-ports = <0>;
			qcom,ports-sinterval-low =	/bits/ 8 <0x01 0x01 0x03 0x03>;
			qcom,ports-offset1 =		/bits/ 8 <0x00 0x00 0x01 0x01>;
			qcom,ports-offset2 =		/bits/ 8 <0x00 0x00 0x00 0x00>;
			qcom,ports-hstart =		/bits/ 8 <0xff 0xff 0xff 0xff>;
			qcom,ports-hstop =		/bits/ 8 <0xff 0xff 0xff 0xff>;
			qcom,ports-word-length =	/bits/ 8 <0xff 0xff 0xff 0xff>;
			qcom,ports-block-pack-mode =	/bits/ 8 <0xff 0xff 0xff 0xff>;
			qcom,ports-block-group-count =	/bits/ 8 <0xff 0xff 0xff 0xff>;
			qcom,ports-lane-control =	/bits/ 8 <0x01 0x02 0x00 0x00>;

			#address-cells = <2>;
			#size-cells = <0>;
			#sound-dai-cells = <1>;
			status = "disabled";
		};

		lpass_vamacro: codec@33f0000 {
			compatible = "qcom,sm8450-lpass-va-macro";
			reg = <0 0x033f0000 0 0x1000>;
			clocks = <&q6prmcc LPASS_CLK_ID_TX_CORE_MCLK LPASS_CLK_ATTRIBUTE_COUPLE_NO>,
				 <&q6prmcc LPASS_HW_MACRO_VOTE LPASS_CLK_ATTRIBUTE_COUPLE_NO>,
				 <&q6prmcc LPASS_HW_DCODEC_VOTE LPASS_CLK_ATTRIBUTE_COUPLE_NO>,
				 <&q6prmcc LPASS_CLK_ID_RX_CORE_MCLK2_2X_MCLK LPASS_CLK_ATTRIBUTE_COUPLE_NO>;
			clock-names = "mclk", "macro", "dcodec", "npl";

			#clock-cells = <0>;
			clock-output-names = "fsgen";
			#sound-dai-cells = <1>;
			status = "disabled";
		};

		lpass_tlmm: pinctrl@3440000 {
			compatible = "qcom,sm7550-lpass-lpi-pinctrl";
			reg = <0 0x03440000 0 0x20000>,
			      <0 0x034da000 0 0x10000>;
			gpio-controller;
			#gpio-cells = <2>;
			gpio-ranges = <&lpass_tlmm 0 0 23>;

			clocks = <&q6prmcc LPASS_HW_MACRO_VOTE LPASS_CLK_ATTRIBUTE_COUPLE_NO>,
				 <&q6prmcc LPASS_HW_DCODEC_VOTE LPASS_CLK_ATTRIBUTE_COUPLE_NO>;
			clock-names = "core", "audio";

			tx_swr_active: tx-swr-active-state {
				clk-pins {
					pins = "gpio0";
					function = "swr_tx_clk";
					drive-strength = <4>;
					slew-rate = <1>;
					bias-disable;
				};

				data-pins {
					pins = "gpio1", "gpio2", "gpio14";
					function = "swr_tx_data";
					drive-strength = <4>;
					slew-rate = <1>;
					bias-bus-hold;
				};
			};

			rx_swr_active: rx-swr-active-state {
				clk-pins {
					pins = "gpio3";
					function = "swr_rx_clk";
					drive-strength = <2>;
					slew-rate = <1>;
					bias-disable;
				};

				data-pins {
					pins = "gpio4", "gpio5";
					function = "swr_rx_data";
					drive-strength = <2>;
					slew-rate = <1>;
					bias-bus-hold;
				};
			};

			wsa_swr_active: wsa-swr-active-state {
				clk-pins {
					pins = "gpio10";
					function = "wsa_swr_clk";
					drive-strength = <2>;
					slew-rate = <1>;
					bias-disable;
				};

				data-pins {
					pins = "gpio11";
					function = "wsa_swr_data";
					drive-strength = <2>;
					slew-rate = <1>;
					bias-bus-hold;
				};
			};

			wsa2_swr_active: wsa2-swr-active-state {
				clk-pins {
					pins = "gpio12";
					function = "wsa2_swr_clk";
					drive-strength = <2>;
					slew-rate = <1>;
					bias-disable;
				};

				data-pins {
					pins = "gpio13";
					function = "wsa2_swr_data";
					drive-strength = <2>;
					slew-rate = <1>;
					bias-bus-hold;
				};
			};
		};

		sdhc_2: mmc@8804000 {
			compatible = "qcom,sm7550-sdhci", "qcom,sdhci-msm-v5";
			reg = <0 0x08804000 0 0x1000>;

			interrupts = <GIC_SPI 207 IRQ_TYPE_LEVEL_HIGH 0>,
				     <GIC_SPI 223 IRQ_TYPE_LEVEL_HIGH 0>;
			interrupt-names = "hc_irq", "pwr_irq";

			clocks = <&gcc GCC_SDCC2_AHB_CLK>,
				 <&gcc GCC_SDCC2_APPS_CLK>,
				 <&bi_tcxo_div2>;
			clock-names = "iface", "core", "xo";
			iommus = <&apps_smmu 0x4C0 0>;
			qcom,dll-config = <0x0007642c>;
			qcom,ddr-config = <0x80040868>;
			power-domains = <&rpmhpd RPMHPD_CX>;
			operating-points-v2 = <&sdhc2_opp_table>;

			interconnects = <&aggre2_noc MASTER_SDCC_2 QCOM_ICC_TAG_ALWAYS
					 &mc_virt SLAVE_EBI1 QCOM_ICC_TAG_ALWAYS>,
					<&gem_noc MASTER_APPSS_PROC QCOM_ICC_TAG_ACTIVE_ONLY
					 &config_noc SLAVE_SDCC_2 QCOM_ICC_TAG_ACTIVE_ONLY>;
			interconnect-names = "sdhc-ddr", "cpu-sdhc";
			bus-width = <4>;
			max-sd-hs-hz = <37500000>;
			dma-coherent;

			status = "disabled";

			sdhc2_opp_table: opp-table {
				compatible = "operating-points-v2";

				opp-19200000 {
					opp-hz = /bits/ 64 <19200000>;
					required-opps = <&rpmhpd_opp_min_svs>;
				};

				opp-50000000 {
					opp-hz = /bits/ 64 <50000000>;
					required-opps = <&rpmhpd_opp_low_svs>;
				};

				opp-100000000 {
					opp-hz = /bits/ 64 <100000000>;
					required-opps = <&rpmhpd_opp_svs>;
				};

				opp-202000000 {
					opp-hz = /bits/ 64 <202000000>;
					required-opps = <&rpmhpd_opp_svs_l1>;
				};
			};
		};

		iris: video-codec@aa00000 {
			compatible = "qcom,sm7550-iris";

			reg = <0 0x0aa00000 0 0xf0000>;
			interrupts = <GIC_SPI 174 IRQ_TYPE_LEVEL_HIGH 0>;

			power-domains = <&videocc VIDEO_CC_MVS0C_GDSC>,
					<&videocc VIDEO_CC_MVS0_GDSC>,
					<&rpmhpd RPMHPD_MXC>,
					<&rpmhpd RPMHPD_MMCX>;
			power-domain-names = "venus",
					     "vcodec0",
					     "mxc",
					     "mmcx";
			operating-points-v2 = <&iris_opp_table>;

			clocks = <&videocc VIDEO_CC_MVSC_CTL_AXI_CLK>,
				 <&videocc VIDEO_CC_MVS0_AXI_CLK>,
				 <&videocc VIDEO_CC_MVS0C_CLK>,
				 <&videocc VIDEO_CC_MVS0_CLK>,
				 <&videocc VIDEO_CC_VENUS_AHB_CLK>,
				 <&videocc VIDEO_CC_MVS0_CLK_SRC>;
			clock-names = "video_ctl_axi",
				      "video_mvs0_axi",
				      "core",
				      "vcodec0_core",
				      "iface",
				      "vcodec0_src";

			interconnects = <&gem_noc MASTER_APPSS_PROC QCOM_ICC_TAG_ACTIVE_ONLY
					 &config_noc SLAVE_VENUS_CFG QCOM_ICC_TAG_ACTIVE_ONLY>,
					<&mmss_noc MASTER_VIDEO QCOM_ICC_TAG_ALWAYS
					 &mc_virt SLAVE_EBI1 QCOM_ICC_TAG_ALWAYS>;
			interconnect-names = "cpu-cfg",
					     "video-mem";

			memory-region = <&video_mem>;
			firmware-name = "qcom/vpu/vpu20_1v.mbn";

			resets = <&videocc VCODEC_VIDEO_CC_INTERFACE_BCR>,
				 <&videocc VCODEC_VIDEO_CC_MVS0C_BCR>;
			reset-names = "bus", "core";

			iommus = <&apps_smmu 0x1980 0x20>,
				 <&apps_smmu 0x1987 0>;
			dma-coherent;

			/*
			 * IRIS firmware is signed by vendors, only
			 * enable on boards where the proper signed firmware
			 * is available.
			 */
			status = "disabled";

			iris_opp_table: opp-table {
				compatible = "operating-points-v2";

				opp-165000000 {
					opp-hz = /bits/ 64 <165000000>;
					required-opps = <&rpmhpd_opp_svs>,
							<&rpmhpd_opp_low_svs>;
				};

				opp-270000000 {
					opp-hz = /bits/ 64 <270000000>;
					required-opps = <&rpmhpd_opp_svs>,
							<&rpmhpd_opp_svs>;
				};

				opp-366000000 {
					opp-hz = /bits/ 64 <366000000>;
					required-opps = <&rpmhpd_opp_svs>,
							<&rpmhpd_opp_svs_l1>;
				};

				opp-424000000 {
					opp-hz = /bits/ 64 <424000000>;
					required-opps = <&rpmhpd_opp_svs_l1>,
							<&rpmhpd_opp_nom>;
				};

				opp-460000000 {
					opp-hz = /bits/ 64 <460000000>;
					required-opps = <&rpmhpd_opp_nom>,
							<&rpmhpd_opp_turbo>;
				};
			};
		};

        videocc: clock-controller@aaf0000 {
			compatible = "qcom,sm7550-videocc";
			reg = <0 0xaaf0000 0 0x10000>;
			clocks = <&bi_tcxo_div2>,
				 <&gcc GCC_VIDEO_AHB_CLK>;
			power-domains = <&rpmhpd RPMHPD_MMCX>,
					<&rpmhpd RPMHPD_MXC>;
			required-opps = <&rpmhpd_opp_low_svs>,
					<&rpmhpd_opp_low_svs>;
			#clock-cells = <1>;
			#reset-cells = <1>;
			#power-domain-cells = <1>;
		};

		cci0: cci@ac15000 {
			compatible = "qcom,sm7550-cci", "qcom,msm8996-cci";
			reg = <0 0x0ac15000 0 0x1000>;
			interrupts = <GIC_SPI 426 IRQ_TYPE_EDGE_RISING 0>;
			power-domains = <&camcc CAM_CC_CAMSS_TOP_GDSC>;
			clocks = <&camcc CAM_CC_CCI_0_CLK_SRC>,
				 <&camcc CAM_CC_CCI_0_CLK>;
			clock-names = "cci_src", "cci";
			pinctrl-0 = <&cci0_0_default &cci0_1_default>;
			pinctrl-1 = <&cci0_0_sleep &cci0_1_sleep>;
			pinctrl-names = "default", "sleep";
			status = "disabled";
			#address-cells = <1>;
			#size-cells = <0>;

			cci0_i2c0: i2c-bus@0 {
				reg = <0>;
				clock-frequency = <1000000>;
				#address-cells = <1>;
				#size-cells = <0>;
			};

			cci0_i2c1: i2c-bus@1 {
				reg = <1>;
				clock-frequency = <1000000>;
				#address-cells = <1>;
				#size-cells = <0>;
			};
		};

		cci1: cci@ac16000 {
			compatible = "qcom,sm7550-cci", "qcom,msm8996-cci";
			reg = <0 0x0ac16000 0 0x1000>;
			interrupts = <GIC_SPI 427 IRQ_TYPE_EDGE_RISING 0>;
			power-domains = <&camcc CAM_CC_CAMSS_TOP_GDSC>;
			clocks = <&camcc CAM_CC_CCI_1_CLK_SRC>,
				 <&camcc CAM_CC_CCI_1_CLK>;
			clock-names = "cci_src", "cci";
			pinctrl-0 = <&cci1_0_default &cci1_1_default>;
			pinctrl-1 = <&cci1_0_sleep &cci1_1_sleep>;
			pinctrl-names = "default", "sleep";
			status = "disabled";
			#address-cells = <1>;
			#size-cells = <0>;

			cci1_i2c0: i2c-bus@0 {
				reg = <0>;
				clock-frequency = <1000000>;
				#address-cells = <1>;
				#size-cells = <0>;
			};

			cci1_i2c1: i2c-bus@1 {
				reg = <1>;
				clock-frequency = <1000000>;
				#address-cells = <1>;
				#size-cells = <0>;
			};
		};

        camcc: clock-controller@adb0000 {
			compatible = "qcom,sm7550-camcc";
			reg = <0 0xadb0000 0 0x40000>;
			clocks = <&gcc GCC_CAMERA_AHB_CLK>,
				 <&bi_tcxo_div2>,
				 <&bi_tcxo_ao_div2>,
				 <&sleep_clk>;
			power-domains = <&rpmhpd RPMHPD_MMCX>,
					<&rpmhpd RPMHPD_MXC>;
			required-opps = <&rpmhpd_opp_low_svs>,
					<&rpmhpd_opp_low_svs>;
			#clock-cells = <1>;
			#reset-cells = <1>;
			#power-domain-cells = <1>;
		};

        mdss: display-subsystem@ae00000 {
			compatible = "qcom,sm7550-mdss", "qcom,sm8550-mdss";
			reg = <0 0x0ae00000 0 0x1000>;
			reg-names = "mdss";

			interrupts = <GIC_SPI 83 IRQ_TYPE_LEVEL_HIGH 0>;
			interrupt-controller;
			#interrupt-cells = <1>;

			clocks = <&dispcc DISP_CC_MDSS_AHB_CLK>,
				 <&gcc GCC_DISP_AHB_CLK>,
				 <&gcc GCC_DISP_HF_AXI_CLK>,
				 <&dispcc DISP_CC_MDSS_MDP_CLK>;

			resets = <&dispcc DISP_CC_MDSS_CORE_BCR>;

			power-domains = <&dispcc MDSS_GDSC>;

			interconnects = <&mmss_noc MASTER_MDP QCOM_ICC_TAG_ALWAYS
					 &mc_virt SLAVE_EBI1 QCOM_ICC_TAG_ALWAYS>,
					<&gem_noc MASTER_APPSS_PROC QCOM_ICC_TAG_ACTIVE_ONLY
					 &config_noc SLAVE_DISPLAY_CFG QCOM_ICC_TAG_ACTIVE_ONLY>;
			interconnect-names = "mdp0-mem", "cpu-cfg";

			iommus = <&apps_smmu 0x1c00 0x2>;

			#address-cells = <2>;
			#size-cells = <2>;
			ranges;

			status = "disabled";

			mdss_mdp: display-controller@ae01000 {
				compatible = "qcom,sm7550-dpu";
				reg = <0 0x0ae01000 0 0x8f000>,
				      <0 0x0aeb0000 0 0x3000>;
				reg-names = "mdp", "vbif";

				interrupt-parent = <&mdss>;
				interrupts = <0>;

				clocks = <&gcc GCC_DISP_HF_AXI_CLK>,
					 <&dispcc DISP_CC_MDSS_AHB_CLK>,
					 <&dispcc DISP_CC_MDSS_MDP_LUT_CLK>,
					 <&dispcc DISP_CC_MDSS_MDP_CLK>,
					 <&dispcc DISP_CC_MDSS_VSYNC_CLK>;
				clock-names = "bus",
					      "iface",
					      "lut",
					      "core",
					      "vsync";

				assigned-clocks = <&dispcc DISP_CC_MDSS_VSYNC_CLK>;
				assigned-clock-rates = <19200000>;

				operating-points-v2 = <&mdp_opp_table>;
				power-domains = <&rpmhpd RPMHPD_MMCX>;

				ports {
					#address-cells = <1>;
					#size-cells = <0>;

					port@0 {
						reg = <0>;

						dpu_intf1_out: endpoint {
							remote-endpoint = <&mdss_dsi0_in>;
						};
					};

					port@1 {
						reg = <1>;

						dpu_intf0_out: endpoint {
							remote-endpoint = <&mdss_dp0_in>;
						};
					};
				};

				mdp_opp_table: opp-table {
					compatible = "operating-points-v2";

					opp-200000000 {
						opp-hz = /bits/ 64 <200000000>;
						required-opps = <&rpmhpd_opp_low_svs>;
					};

					opp-325000000 {
						opp-hz = /bits/ 64 <325000000>;
						required-opps = <&rpmhpd_opp_svs>;
					};

					opp-375000000 {
						opp-hz = /bits/ 64 <375000000>;
						required-opps = <&rpmhpd_opp_svs_l1>;
					};

					opp-520000000 {
						opp-hz = /bits/ 64 <520000000>;
						required-opps = <&rpmhpd_opp_nom>;
					};
				};
			};

			mdss_dp0: displayport-controller@ae90000 {
				compatible = "qcom,sm7550-dp", "qcom,sm8350-dp";
				reg = <0 0x0ae90000 0 0x200>,
				      <0 0x0ae90200 0 0x200>,
				      <0 0x0ae90400 0 0xc00>,
				      <0 0x0ae91000 0 0x400>,
				      <0 0x0ae91400 0 0x400>;

				interrupt-parent = <&mdss>;
				interrupts = <12>;

				clocks = <&dispcc DISP_CC_MDSS_AHB_CLK>,
					 <&dispcc DISP_CC_MDSS_DPTX0_AUX_CLK>,
					 <&dispcc DISP_CC_MDSS_DPTX0_LINK_CLK>,
					 <&dispcc DISP_CC_MDSS_DPTX0_LINK_INTF_CLK>,
					 <&dispcc DISP_CC_MDSS_DPTX0_PIXEL0_CLK>,
					 <&dispcc DISP_CC_MDSS_DPTX0_PIXEL1_CLK>;
				clock-names = "core_iface",
					      "core_aux",
					      "ctrl_link",
					      "ctrl_link_iface",
					      "stream_pixel",
					      "stream_1_pixel";

				assigned-clocks = <&dispcc DISP_CC_MDSS_DPTX0_LINK_CLK_SRC>,
						  <&dispcc DISP_CC_MDSS_DPTX0_PIXEL0_CLK_SRC>,
						  <&dispcc DISP_CC_MDSS_DPTX0_PIXEL1_CLK_SRC>;
				assigned-clock-parents = <&usb_dp_qmpphy QMP_USB43DP_DP_LINK_CLK>,
							 <&usb_dp_qmpphy QMP_USB43DP_DP_VCO_DIV_CLK>,
							 <&usb_dp_qmpphy QMP_USB43DP_DP_VCO_DIV_CLK>;

				phys = <&usb_dp_qmpphy QMP_USB43DP_DP_PHY>;
				phy-names = "dp";

				#sound-dai-cells = <0>;

				operating-points-v2 = <&dp_opp_table>;
				power-domains = <&rpmhpd RPMHPD_MMCX>;

				status = "disabled";

				ports {
					#address-cells = <1>;
					#size-cells = <0>;

					port@0 {
						reg = <0>;

						mdss_dp0_in: endpoint {
							remote-endpoint = <&dpu_intf0_out>;
						};
					};

					port@1 {
						reg = <1>;

						mdss_dp0_out: endpoint {
							data-lanes = <0 1 2 3>;
							remote-endpoint = <&usb_dp_qmpphy_dp_in>;
						};
					};
				};

				dp_opp_table: opp-table {
					compatible = "operating-points-v2";

					opp-162000000 {
						opp-hz = /bits/ 64 <162000000>;
						required-opps = <&rpmhpd_opp_low_svs_d1>;
					};

					opp-270000000 {
						opp-hz = /bits/ 64 <270000000>;
						required-opps = <&rpmhpd_opp_low_svs>;
					};

					opp-540000000 {
						opp-hz = /bits/ 64 <540000000>;
						required-opps = <&rpmhpd_opp_svs_l1>;
					};

					opp-810000000 {
						opp-hz = /bits/ 64 <810000000>;
						required-opps = <&rpmhpd_opp_nom>;
					};
				};
			};

			mdss_dsi0: dsi@ae94000 {
				compatible = "qcom,sm8550-dsi-ctrl", "qcom,mdss-dsi-ctrl";
				reg = <0 0x0ae94000 0 0x400>;
				reg-names = "dsi_ctrl";

				interrupt-parent = <&mdss>;
				interrupts = <4>;

				clocks = <&dispcc DISP_CC_MDSS_BYTE0_CLK>,
					 <&dispcc DISP_CC_MDSS_BYTE0_INTF_CLK>,
					 <&dispcc DISP_CC_MDSS_PCLK0_CLK>,
					 <&dispcc DISP_CC_MDSS_ESC0_CLK>,
					 <&dispcc DISP_CC_MDSS_AHB_CLK>,
					 <&gcc GCC_DISP_HF_AXI_CLK>;
				clock-names = "byte",
					      "byte_intf",
					      "pixel",
					      "core",
					      "iface",
					      "bus";

				assigned-clocks = <&dispcc DISP_CC_MDSS_BYTE0_CLK_SRC>,
						  <&dispcc DISP_CC_MDSS_PCLK0_CLK_SRC>;
				assigned-clock-parents = <&mdss_dsi0_phy DSI_BYTE_PLL_CLK>,
							 <&mdss_dsi0_phy DSI_PIXEL_PLL_CLK>;

				operating-points-v2 = <&mdss_dsi_opp_table>;
				power-domains = <&rpmhpd RPMHPD_MMCX>;

				phys = <&mdss_dsi0_phy>;
				phy-names = "dsi";

				#address-cells = <1>;
				#size-cells = <0>;

				status = "disabled";

				ports {
					#address-cells = <1>;
					#size-cells = <0>;

					port@0 {
						reg = <0>;

						mdss_dsi0_in: endpoint {
							remote-endpoint = <&dpu_intf1_out>;
						};
					};

					port@1 {
						reg = <1>;

						mdss_dsi0_out: endpoint {
						};
					};
				};

				mdss_dsi_opp_table: opp-table {
					compatible = "operating-points-v2";

					opp-187500000 {
						opp-hz = /bits/ 64 <187500000>;
						required-opps = <&rpmhpd_opp_low_svs>;
					};

					opp-300000000 {
						opp-hz = /bits/ 64 <300000000>;
						required-opps = <&rpmhpd_opp_svs>;
					};

					opp-358000000 {
						opp-hz = /bits/ 64 <358000000>;
						required-opps = <&rpmhpd_opp_svs_l1>;
					};
				};
			};

			mdss_dsi0_phy: phy@ae95000 {
				compatible = "qcom,sm8550-dsi-phy-4nm";
				reg = <0 0x0ae95000 0 0x200>,
				      <0 0x0ae95200 0 0x280>,
				      <0 0x0ae95500 0 0x400>;
				reg-names = "dsi_phy",
					    "dsi_phy_lane",
					    "dsi_pll";

				clocks = <&dispcc DISP_CC_MDSS_AHB_CLK>,
					 <&rpmhcc RPMH_CXO_CLK>;
				clock-names = "iface", "ref";

				#clock-cells = <1>;
				#phy-cells = <0>;

				status = "disabled";
			};
		};

		dispcc: clock-controller@af00000 {
			compatible = "qcom,sm7550-dispcc";
			reg = <0 0x0af00000 0 0x20000>;
			clocks = <&rpmhcc RPMH_CXO_CLK>,
				 <&rpmhcc RPMH_CXO_CLK_A>,
				 <&gcc GCC_DISP_AHB_CLK>,
				 <&sleep_clk>,
				 <&mdss_dsi0_phy DSI_BYTE_PLL_CLK>,
				 <&mdss_dsi0_phy DSI_PIXEL_PLL_CLK>,
				 <&usb_dp_qmpphy QMP_USB43DP_DP_LINK_CLK>,
				 <&usb_dp_qmpphy QMP_USB43DP_DP_VCO_DIV_CLK>;
			power-domains = <&rpmhpd RPMHPD_MMCX>;
			required-opps = <&rpmhpd_opp_low_svs>;
			#clock-cells = <1>;
			#reset-cells = <1>;
			#power-domain-cells = <1>;
		};

		usb_1_hsphy: phy@88e3000 {
			compatible = "qcom,sm7550-snps-eusb2-phy";
			reg = <0x0 0x088e3000 0x0 0x150>;
			#phy-cells = <0>;

			clocks = <&tcsr TCSR_USB2_CLKREF_EN>;
			clock-names = "ref";

			resets = <&gcc GCC_QUSB2PHY_PRIM_BCR>;

			status = "disabled";
		};


		usb_dp_qmpphy: phy@88e8000 {
			compatible = "qcom,sm7550-qmp-usb3-dp-phy";
			reg = <0x0 0x088e8000 0x0 0x3000>;

			clocks = <&gcc GCC_USB3_PRIM_PHY_AUX_CLK>,
				 <&rpmhcc RPMH_CXO_CLK>,
				 <&gcc GCC_USB3_PRIM_PHY_COM_AUX_CLK>,
				 <&gcc GCC_USB3_PRIM_PHY_PIPE_CLK>;
			clock-names = "aux", "ref", "com_aux", "usb3_pipe";

			power-domains = <&gcc USB3_PHY_GDSC>;

			resets = <&gcc GCC_USB3_PHY_PRIM_BCR>,
				 <&gcc GCC_USB3_DP_PHY_PRIM_BCR>;
			reset-names = "phy", "common";

			#clock-cells = <1>;
			#phy-cells = <1>;

			mode-switch;
			orientation-switch;

			status = "disabled";

			ports {
				#address-cells = <1>;
				#size-cells = <0>;

				port@0 {
					reg = <0>;

					usb_dp_qmpphy_out: endpoint {
					};
				};

				port@1 {
					reg = <1>;

					usb_dp_qmpphy_usb_ss_in: endpoint {
						remote-endpoint = <&usb_1_dwc3_ss>;
					};
				};

				port@2 {
					reg = <2>;

					usb_dp_qmpphy_dp_in: endpoint {
						remote-endpoint = <&mdss_dp0_out>;
					};
				};
			};
		};


		usb_1: usb@a600000 {
			compatible = "qcom,sm7550-dwc3", "qcom,snps-dwc3";
			reg = <0x0 0x0a600000 0x0 0x100000>;

			clocks = <&gcc GCC_CFG_NOC_USB3_PRIM_AXI_CLK>,
				 <&gcc GCC_USB30_PRIM_MASTER_CLK>,
				 <&gcc GCC_AGGRE_USB3_PRIM_AXI_CLK>,
				 <&gcc GCC_USB30_PRIM_SLEEP_CLK>,
				 <&gcc GCC_USB30_PRIM_MOCK_UTMI_CLK>,
				 <&tcsr TCSR_USB3_CLKREF_EN>;
			clock-names = "cfg_noc",
				      "core",
				      "iface",
				      "sleep",
				      "mock_utmi",
				      "xo";

			assigned-clocks = <&gcc GCC_USB30_PRIM_MOCK_UTMI_CLK>,
					  <&gcc GCC_USB30_PRIM_MASTER_CLK>;
			assigned-clock-rates = <19200000>, <200000000>;

			interrupts-extended = <&intc GIC_SPI 133 IRQ_TYPE_LEVEL_HIGH 0>,
					      <&intc GIC_SPI 130 IRQ_TYPE_LEVEL_HIGH 0>,
					      <&intc GIC_SPI 131 IRQ_TYPE_LEVEL_HIGH 0>,
					      <&pdc 14 IRQ_TYPE_EDGE_BOTH>,
					      <&pdc 15 IRQ_TYPE_EDGE_BOTH>,
					      <&pdc 17 IRQ_TYPE_LEVEL_HIGH>;
			interrupt-names = "dwc_usb3",
					  "pwr_event",
					  "hs_phy_irq",
					  "dp_hs_phy_irq",
					  "dm_hs_phy_irq",
					  "ss_phy_irq";

			power-domains = <&gcc USB30_PRIM_GDSC>;
			required-opps = <&rpmhpd_opp_nom>;

			resets = <&gcc GCC_USB30_PRIM_BCR>;

			interconnects = <&aggre1_noc MASTER_USB3_0 QCOM_ICC_TAG_ALWAYS
					 &mc_virt SLAVE_EBI1 QCOM_ICC_TAG_ALWAYS>,
					<&gem_noc MASTER_APPSS_PROC QCOM_ICC_TAG_ACTIVE_ONLY
					 &config_noc SLAVE_USB3_0 QCOM_ICC_TAG_ACTIVE_ONLY>;
			interconnect-names = "usb-ddr", "apps-usb";

			iommus = <&apps_smmu 0x80 0x0>;

			phys = <&usb_1_hsphy>,
			       <&usb_dp_qmpphy QMP_USB43DP_USB3_PHY>;
			phy-names = "usb2-phy", "usb3-phy";

			snps,hird-threshold = /bits/ 8 <0x0>;
			snps,usb2-gadget-lpm-disable;
			snps,dis_u2_susphy_quirk;
			snps,dis_enblslpm_quirk;
			snps,dis-u1-entry-quirk;
			snps,dis-u2-entry-quirk;
			snps,is-utmi-l1-suspend;
			snps,usb3_lpm_capable;
			snps,usb2-lpm-disable;
			snps,has-lpm-erratum;
			tx-fifo-resize;

			dma-coherent;

			usb-role-switch;

			status = "disabled";

			ports {
				#address-cells = <1>;
				#size-cells = <0>;

				port@0 {
					reg = <0>;

					usb_1_dwc3_hs: endpoint {
					};
				};

				port@1 {
					reg = <1>;

					usb_1_dwc3_ss: endpoint {
						remote-endpoint = <&usb_dp_qmpphy_usb_ss_in>;
					};
				};
			};
		};

		pdc: interrupt-controller@b220000 {
			compatible = "qcom,sm7550-pdc", "qcom,pdc";
			reg = <0 0x0b220000 0 0x30000>, <0 0x174000f0 0 0x64>;
			qcom,pdc-ranges = <0 480 94>, <94 609 31>,
					  <125 63 1>, <126 716 12>,
					  <138 470 5>;
			#interrupt-cells = <2>;
			interrupt-parent = <&intc>;
			interrupt-controller;
		};

		tsens0: thermal-sensor@c271000 {
			compatible = "qcom,sm7550-tsens", "qcom,tsens-v2";
			reg = <0 0x0c271000 0 0x1ff>, /* TM */
			      <0 0x0c222000 0 0x1ff>; /* SROT */
			#qcom,sensors = <16>;
			interrupts = <GIC_SPI 506 IRQ_TYPE_LEVEL_HIGH 0>,
				     <GIC_SPI 640 IRQ_TYPE_LEVEL_HIGH 0>;
			interrupt-names = "uplow", "critical";
			#thermal-sensor-cells = <1>;
		};

		tsens1: thermal-sensor@c272000 {
			compatible = "qcom,sm7550-tsens", "qcom,tsens-v2";
			reg = <0 0x0c272000 0 0x1000>, /* TM */
			      <0 0x0c223000 0 0x1000>; /* SROT */
			#qcom,sensors = <11>;
			interrupts = <GIC_SPI 507 IRQ_TYPE_LEVEL_HIGH 0>,
				     <GIC_SPI 641 IRQ_TYPE_LEVEL_HIGH 0>;
			interrupt-names = "uplow", "critical";
			#thermal-sensor-cells = <1>;
		};

		aoss_qmp: power-management@c300000 {
			compatible = "qcom,sm7550-aoss-qmp", "qcom,aoss-qmp";
			reg = <0 0x0c300000 0 0x400>;
			interrupt-parent = <&ipcc>;
			interrupts-extended = <&ipcc IPCC_CLIENT_AOP IPCC_MPROC_SIGNAL_GLINK_QMP
						     IRQ_TYPE_EDGE_RISING>;
			mboxes = <&ipcc IPCC_CLIENT_AOP IPCC_MPROC_SIGNAL_GLINK_QMP>;

			#clock-cells = <0>;
		};

		sram@c3f0000 {
			compatible = "qcom,rpmh-stats";
			reg = <0 0x0c3f0000 0 0x400>;
			qcom,qmp = <&aoss_qmp>;
		};

		spmi_bus: spmi@c400000 {
			compatible = "qcom,spmi-pmic-arb";
			reg = <0 0x0c400000 0 0x3000>,
			      <0 0x0c500000 0 0x400000>,
			      <0 0x0c440000 0 0x80000>,
			      <0 0x0c4c0000 0 0x20000>,
			      <0 0x0c42d000 0 0x4000>;
			reg-names = "core", "chnls", "obsrvr", "intr", "cnfg";
			interrupt-names = "periph_irq";
			interrupts-extended = <&pdc 1 IRQ_TYPE_LEVEL_HIGH>;
			qcom,ee = <0>;
			qcom,channel = <0>;
			qcom,bus-id = <0>;
			#address-cells = <2>;
			#size-cells = <0>;
			interrupt-controller;
			#interrupt-cells = <4>;
		};

        tlmm: pinctrl@f000000 {
            compatible = "qcom,sm7550-pinctrl";
            reg = <0x0F000000 0x1000000>;
            interrupts = <GIC_SPI 208 IRQ_TYPE_LEVEL_HIGH>;
            gpio-controller;
            #gpio-cells = <2>;
            interrupt-controller;
            #interrupt-cells = <2>;
            qcom,gpios-reserved = <24 25 26 27 111 112>;
            wakeup-parent = <&pdc>;

			qup_i2c0_data_clk: qup-i2c0-data-clk-state {
				/* SDA, SCL */
				pins = "gpio0", "gpio1";
				function = "qup0_se0";
				drive-strength = <2>;
				bias-pull-up = <2200>;
			};

            qup_i2c1_data_clk: qup-i2c1-data-clk-state {
				/* SDA, SCL */
				pins = "gpio4", "gpio5";
				function = "qup0_se1";
				drive-strength = <2>;
				bias-pull-up = <2200>;
			};

            qup_i2c2_data_clk: qup-i2c2-data-clk-state {
				/* SDA, SCL */
				pins = "gpio8", "gpio9";
				function = "qup0_se2";
				drive-strength = <2>;
				bias-pull-up = <2200>;
			};

            qup_i2c3_data_clk: qup-i2c3-data-clk-state {
				/* SDA, SCL */
				pins = "gpio12", "gpio13";
				function = "qup0_se3";
				drive-strength = <2>;
				bias-pull-up = <2200>;
			};

            qup_i2c4_data_clk: qup-i2c4-data-clk-state {
				/* SDA, SCL */
				pins = "gpio16", "gpio17";
				function = "qup0_se4";
				drive-strength = <2>;
				bias-pull-up = <2200>;
			};

            qup_i2c6_data_clk: qup-i2c6-data-clk-state {
				/* SDA, SCL */
				pins = "gpio24", "gpio25";
				function = "qup0_se6";
				drive-strength = <2>;
				bias-pull-up = <2200>;
			};

            qup_i2c7_data_clk: qup-i2c7-data-clk-state {
				/* SDA, SCL */
				pins = "gpio28", "gpio29";
				function = "qup0_se7";
				drive-strength = <2>;
				bias-pull-up = <2200>;
			};

            qup_i2c8_data_clk: qup-i2c8-data-clk-state {
				/* SDA, SCL */
				pins = "gpio32", "gpio33";
				function = "qup1_se0";
				drive-strength = <2>;
				bias-pull-up = <2200>;
			};

            qup_i2c9_data_clk: qup-i2c9-data-clk-state {
				/* SDA, SCL */
				pins = "gpio36", "gpio37";
				function = "qup1_se1";
				drive-strength = <2>;
				bias-pull-up = <2200>;
			};

            qup_i2c11_data_clk: qup-i2c11-data-clk-state {
				/* SDA, SCL */
				pins = "gpio44", "gpio45";
				function = "qup1_se3";
				drive-strength = <2>;
				bias-pull-up = <2200>;
			};

            qup_i2c12_data_clk: qup-i2c12-data-clk-state {
				/* SDA, SCL */
				pins = "gpio48", "gpio49";
				function = "qup1_se4";
				drive-strength = <2>;
				bias-pull-up = <2200>;
			};

            qup_i2c13_data_clk: qup-i2c13-data-clk-state {
				/* SDA, SCL */
				pins = "gpio52", "gpio53";
				function = "qup1_se5";
				drive-strength = <2>;
				bias-pull-up = <2200>;
			};
            
            qup_i2c14_data_clk: qup-i2c14-data-clk-state {
				/* SDA, SCL */
				pins = "gpio56", "gpio57";
				function = "qup1_se6";
				drive-strength = <2>;
				bias-pull-up = <2200>;
			};

            qup_i2c15_data_clk: qup-i2c15-data-clk-state {
				/* SDA, SCL */
				pins = "gpio128", "gpio129";
				function = "qup1_se7";
				drive-strength = <2>;
				bias-pull-up = <2200>;
			};

			qup_spi0_cs: qup-spi0-cs-state {
				pins = "gpio3";
				function = "qup0_se0";
				drive-strength = <6>;
				bias-disable;
			};

            qup_spi0_data_clk: qup-spi0-data-clk-state {
				/* MISO, MOSI, CLK */
				pins = "gpio0", "gpio1", "gpio2";
				function = "qup0_se0";
				drive-strength = <6>;
				bias-disable;
			};

			qup_spi1_cs: qup-spi1-cs-state {
				pins = "gpio7";
				function = "qup0_se1";
				drive-strength = <6>;
				bias-disable;
			};

            qup_spi1_data_clk: qup-spi1-data-clk-state {
				/* MISO, MOSI, CLK */
				pins = "gpio4", "gpio5", "gpio6";
				function = "qup0_se1";
				drive-strength = <6>;
				bias-disable;
			};

			qup_spi2_cs: qup-spi2-cs-state {
				pins = "gpio11";
				function = "qup0_se2";
				drive-strength = <6>;
				bias-disable;
			};

            qup_spi2_data_clk: qup-spi2-data-clk-state {
				/* MISO, MOSI, CLK */
				pins = "gpio8", "gpio9", "gpio10";
				function = "qup0_se2";
				drive-strength = <6>;
				bias-disable;
			};

			qup_spi3_cs: qup-spi3-cs-state {
				pins = "gpio15";
				function = "qup0_se3";
				drive-strength = <6>;
				bias-disable;
			};

            qup_spi3_data_clk: qup-spi3-data-clk-state {
				/* MISO, MOSI, CLK */
				pins = "gpio12", "gpio13", "gpio14";
				function = "qup0_se3";
				drive-strength = <6>;
				bias-disable;
			};

			qup_spi4_cs: qup-spi4-cs-state {
				pins = "gpio19";
				function = "qup0_se4";
				drive-strength = <6>;
				bias-disable;
			};

            qup_spi4_data_clk: qup-spi4-data-clk-state {
				/* MISO, MOSI, CLK */
				pins = "gpio16", "gpio17", "gpio18";
				function = "qup0_se4";
				drive-strength = <6>;
				bias-disable;
			};

			qup_spi6_cs: qup-spi6-cs-state {
				pins = "gpio27";
				function = "qup0_se5";
				drive-strength = <6>;
				bias-disable;
			};

            qup_spi6_data_clk: qup-spi6-data-clk-state {
				/* MISO, MOSI, CLK */
				pins = "gpio24", "gpio25", "gpio26";
				function = "qup0_se5";
				drive-strength = <6>;
				bias-disable;
			};

			qup_spi7_cs: qup-spi7-cs-state {
				pins = "gpio3";
				function = "qup0_se6";
				drive-strength = <6>;
				bias-disable;
			};

            qup_spi7_data_clk: qup-spi7-data-clk-state {
				/* MISO, MOSI, CLK */
				pins = "gpio28", "gpio29", "gpio30";
				function = "qup0_se6";
				drive-strength = <6>;
				bias-disable;
			};

			qup_spi8_cs: qup-spi8-cs-state {
				pins = "gpio35";
				function = "qup1_se0";
				drive-strength = <6>;
				bias-disable;
			};

            qup_spi8_data_clk: qup-spi8-data-clk-state {
				/* MISO, MOSI, CLK */
				pins = "gpio32", "gpio33", "gpio34";
				function = "qup1_se0";
				drive-strength = <6>;
				bias-disable;
			};

			qup_spi9_cs: qup-spi9-cs-state {
				pins = "gpio39";
				function = "qup1_se1";
				drive-strength = <6>;
				bias-disable;
			};

            qup_spi9_data_clk: qup-spi9-data-clk-state {
				/* MISO, MOSI, CLK */
				pins = "gpio36", "gpio37", "gpio38";
				function = "qup1_se1";
				drive-strength = <6>;
				bias-disable;
			};

			qup_spi11_cs: qup-spi11-cs-state {
				pins = "gpio47";
				function = "qup1_se3";
				drive-strength = <6>;
				bias-disable;
			};

            qup_spi11_data_clk: qup-spi11-data-clk-state {
				/* MISO, MOSI, CLK */
				pins = "gpio44", "gpio45", "gpio46";
				function = "qup1_se3";
				drive-strength = <6>;
				bias-disable;
			};

			qup_spi12_cs: qup-spi12-cs-state {
				pins = "gpio51";
				function = "qup1_se4";
				drive-strength = <6>;
				bias-disable;
			};

            qup_spi12_data_clk: qup-spi12-data-clk-state {
				/* MISO, MOSI, CLK */
				pins = "gpio48", "gpio49", "gpio50";
				function = "qup1_se4";
				drive-strength = <6>;
				bias-disable;
			};

			qup_spi13_cs: qup-spi13-cs-state {
				pins = "gpio55";
				function = "qup1_se5";
				drive-strength = <6>;
				bias-disable;
			};

            qup_spi13_data_clk: qup-spi13-data-clk-state {
				/* MISO, MOSI, CLK */
				pins = "gpio52", "gpio53", "gpio54";
				function = "qup1_se5";
				drive-strength = <6>;
				bias-disable;
			};

			qup_spi14_cs: qup-spi14-cs-state {
				pins = "gpio59";
				function = "qup1_se6";
				drive-strength = <6>;
				bias-disable;
			};

            qup_spi14_data_clk: qup-spi14-data-clk-state {
				/* MISO, MOSI, CLK */
				pins = "gpio56", "gpio57", "gpio58";
				function = "qup1_se6";
				drive-strength = <6>;
				bias-disable;
			};

			qup_spi15_cs: qup-spi15-cs-state {
				pins = "gpio131";
				function = "qup1_se7";
				drive-strength = <6>;
				bias-disable;
			};

            qup_spi15_data_clk: qup-spi15-data-clk-state {
				/* MISO, MOSI, CLK */
				pins = "gpio128", "gpio129", "gpio130";
				function = "qup1_se7";
				drive-strength = <6>;
				bias-disable;
			};

            qup_uart5_default: qup-uart5-default-state {
				/* TX, RX */
				pins = "gpio22", "gpio23";
				function = "qup0_se5";
				drive-strength = <2>;
				bias-disable;
			};

            qup_uart10_default: qup-uart19-default-state {
				/* TX, RX */
				pins = "gpio42", "gpio43";
				function = "qup1_se2";
				drive-strength = <2>;
				bias-pull-up;
			};

			qup_uart10_cts_rts: qup-uart10-cts-rts-state {
				/* CTS, RTS */
				pins = "gpio40", "gpio41";
				function = "qup1_se2";
				drive-strength = <2>;
				bias-pull-down;
			};

			sdc2_default: sdc2-default-state {
				clk-pins {
					pins = "sdc2_clk";
					bias-disable;
					drive-strength = <16>;
				};

				cmd-pins {
					pins = "sdc2_cmd";
					bias-pull-up;
					drive-strength = <10>;
				};

				data-pins {
					pins = "sdc2_data";
					bias-pull-up;
					drive-strength = <10>;
				};

				sd-cd-pins {
					pins = "gpio149";
					bias-pull-up;
					drive-strength = <2>;
				};
			};

			sdc2_sleep: sdc2-sleep-state {
				clk-pins {
					pins = "sdc2_clk";
					bias-disable;
					drive-strength = <2>;
				};

				cmd-pins {
					pins = "sdc2_cmd";
					bias-pull-up;
					drive-strength = <2>;
				};

				data-pins {
					pins = "sdc2_data";
					bias-pull-up;
					drive-strength = <2>;
				};

				sd-cd-pins {
					pins = "gpio149";
					bias-disable;
					drive-strength = <2>;
				};
			};


            /* touchscreen pins */
            pmx_ts_active {
                ts_active: ts_active {
                    mux {
                        pins = "gpio28", "gpio21";
                        function = "gpio";
                    };

                    config {
                        pins = "gpio28", "gpio21";
                        drive-strength = <8>;
                        bias-pull-up;
                    };
                };
            };

            pmx_ts_reset_suspend {
                ts_reset_suspend: ts_reset_suspend {
                    mux {
                        pins = "gpio28";
                        function = "gpio";
                    };

                    config {
                        pins = "gpio28";
                        drive-strength = <2>;
                        bias-pull-down;
                    };
                };
            };

            pmx_ts_int_suspend {
                ts_int_suspend: ts_int_suspend {
                    mux {
                        pins = "gpio21";
                        function = "gpio";
                    };

                    config {
                        pins = "gpio21";
                        drive-strength = <2>;
                        bias-pull-down;
                    };
                };
            };

            pmx_ts_release {
                ts_release: ts_release {
                    mux {
                        pins = "gpio28", "gpio21";
                        function = "gpio";
                    };

                    config {
                        pins = "gpio28", "gpio21";
                        drive-strength = <2>;
                        bias-disable;
                    };
                };
            };

            i2s0_sck {
                i2s0_sck_sleep: i2s0_sck_sleep {
                    mux {
                        pins = "gpio60";
                        function = "gpio";
                    };

                    config {
                        pins = "gpio60";
                        drive-strength = <2>;   /* 2 mA */
                        bias-pull-down;         /* PULL DOWN */
                        input-enable;
                    };
                };

                i2s0_sck_active: i2s0_sck_active {
                    mux {
                        pins = "gpio60";
                        function = "i2s0_sck";
                    };

                    config {
                        pins = "gpio60";
                        drive-strength = <8>;   /* 8 mA */
                        bias-disable;           /* NO PULL */
                        output-high;
                    };
                };
            };

            i2s0_ws {
                i2s0_ws_sleep: i2s0_ws_sleep {
                    mux {
                        pins = "gpio61";
                        function = "gpio";
                    };

                    config {
                        pins = "gpio61";
                        drive-strength = <2>;   /* 2 mA */
                        bias-pull-down;         /* PULL DOWN */
                        input-enable;
                    };
                };

                i2s0_ws_active: i2s0_ws_active {
                    mux {
                        pins = "gpio61";
                        function = "i2s0_ws";
                    };

                    config {
                        pins = "gpio61";
                        drive-strength = <8>;   /* 8 mA */
                        bias-disable;           /* NO PULL */
                        output-high;
                    };
                };
            };

            i2s0_sd0 {
                i2s0_sd0_sleep: i2s0_sd0_sleep {
                    mux {
                        pins = "gpio62";
                        function = "gpio";
                    };

                    config {
                        pins = "gpio62";
                        drive-strength = <2>;   /* 2 mA */
                        bias-pull-down;         /* PULL DOWN */
                        input-enable;
                    };
                };

                i2s0_sd0_active: i2s0_sd0_active {
                    mux {
                        pins = "gpio62";
                        function = "i2s0_data0";
                    };

                    config {
                        pins = "gpio62";
                        drive-strength = <8>;   /* 8 mA */
                        bias-disable;           /* NO PULL */
                        output-high;
                    };
                };
            };

            i2s0_sd1 {
                i2s0_sd1_sleep: i2s0_sd1_sleep {
                    mux {
                        pins = "gpio63";
                        function = "gpio";
                    };

                    config {
                        pins = "gpio63";
                        drive-strength = <2>;   /* 2 mA */
                        bias-pull-down;         /* PULL DOWN */
                        input-enable;
                    };
                };

                i2s0_sd1_active: i2s0_sd1_active {
                    mux {
                        pins = "gpio63";
                        function = "i2s0_data1";
                    };

                    config {
                        pins = "gpio63";
                        drive-strength = <8>;   /* 8 mA */
                        bias-disable;           /* NO PULL */
                        output-high;
                    };
                };
            };

            /* WCD reset pin */
            wcd_reset_active: wcd_reset_active {
                mux {
                    pins = "gpio54";
                    function = "gpio";
                };

                config {
                    pins = "gpio54";
                    drive-strength = <16>;
                    output-high;
                };
            };

            wcd_reset_sleep: wcd_reset_sleep {
                mux {
                    pins = "gpio54";
                    function = "gpio";
                };

                config {
                    pins = "gpio54";
                    drive-strength = <16>;
                    bias-disable;
                    output-low;
                };
            };

            usb_phy_ps: usb_phy_ps {
                usb3phy_portselect_default: usb3phy_portselect_default {
                    mux {
                        pins = "gpio83";
                        function = "usb0_phy_ps";
                    };

                    config {
                        pins = "gpio83";
                        bias-pull-down;
                        drive-strength = <2>;
                    };
                };

                usb3phy_portselect_gpio: usb3phy_portselect_gpio {
                    mux {
                        pins = "gpio83";
                        function = "gpio";
                    };

                    config {
                        pins = "gpio83";
                        drive-strength = <2>;
                        bias-pull-down;
                        input-enable;
                    };
                };
            };

			cci0_0_default: cci0-0-default-state {
				sda-pins {
					pins = "gpio70";
					function = "cci_i2c_sda0";
					drive-strength = <2>;
					bias-pull-up;
				};

				scl-pins {
					pins = "gpio71";
					function = "cci_i2c_scl0";
					drive-strength = <2>;
					bias-pull-up;
				};
			};

			cci0_0_sleep: cci0-0-sleep-state {
				sda-pins {
					pins = "gpio70";
					function = "cci_i2c_sda0";
					drive-strength = <2>;
					bias-pull-down;
				};

				scl-pins {
					pins = "gpio71";
					function = "cci_i2c_scl0";
					drive-strength = <2>;
					bias-pull-down;
				};
			};

			cci0_1_default: cci0-1-default-state {
				sda-pins {
					pins = "gpio72";
					function = "cci_i2c_sda1";
					drive-strength = <2>;
					bias-pull-up;
				};

				scl-pins {
					pins = "gpio73";
					function = "cci_i2c_scl1";
					drive-strength = <2>;
					bias-pull-up;
				};
			};

			cci0_1_sleep: cci0-1-sleep-state {
				sda-pins {
					pins = "gpio72";
					function = "cci_i2c_sda1";
					drive-strength = <2>;
					bias-pull-down;
				};

				scl-pins {
					pins = "gpio73";
					function = "cci_i2c_scl1";
					drive-strength = <2>;
					bias-pull-down;
				};
			};

			cci1_0_default: cci1-0-default-state {
				sda-pins {
					pins = "gpio74";
					function = "cci_i2c_sda2";
					drive-strength = <2>;
					bias-pull-up;
				};

				scl-pins {
					pins = "gpio75";
					function = "cci_i2c_scl2";
					drive-strength = <2>;
					bias-pull-up;
				};
			};

			cci1_0_sleep: cci1-0-sleep-state {
				sda-pins {
					pins = "gpio74";
					function = "cci_i2c_sda2";
					drive-strength = <2>;
					bias-pull-down;
				};

				scl-pins {
					pins = "gpio75";
					function = "cci_i2c_scl2";
					drive-strength = <2>;
					bias-pull-down;
				};
			};

			cci1_1_default: cci1-1-default-state {
				sda-pins {
					pins = "gpio76";
					function = "cci_i2c_sda3";
					drive-strength = <2>;
					bias-pull-up;
				};

				scl-pins {
					pins = "gpio77";
					function = "cci_i2c_scl3";
					drive-strength = <2>;
					bias-pull-up;
				};
			};

			cci1_1_sleep: cci1-1-sleep-state {
				sda-pins {
					pins = "gpio76";
					function = "cci_i2c_sda3";
					drive-strength = <2>;
					bias-pull-down;
				};

				scl-pins {
					pins = "gpio77";
					function = "cci_i2c_scl3";
					drive-strength = <2>;
					bias-pull-down;
				};
			};

            trigout_a: trigout_a {
                mux {
                    pins = "gpio91";
                    function = "qdss_cti";
                };

                config {
                    pins = "gpio91";
                    drive-strength = <2>;
                    bias-disable;
                };
            };
        }; // tlmm

		apps_smmu: iommu@15000000 {
			compatible = "qcom,sm7550-smmu-500", "qcom,smmu-500", "arm,mmu-500";
			reg = <0 0x15000000 0 0x100000>;
			#iommu-cells = <2>;
			#global-interrupts = <1>;
			interrupts = <GIC_SPI 65 IRQ_TYPE_LEVEL_HIGH 0>,
				     <GIC_SPI 97 IRQ_TYPE_LEVEL_HIGH 0>,
				     <GIC_SPI 98 IRQ_TYPE_LEVEL_HIGH 0>,
				     <GIC_SPI 99 IRQ_TYPE_LEVEL_HIGH 0>,
				     <GIC_SPI 100 IRQ_TYPE_LEVEL_HIGH 0>,
				     <GIC_SPI 101 IRQ_TYPE_LEVEL_HIGH 0>,
				     <GIC_SPI 102 IRQ_TYPE_LEVEL_HIGH 0>,
				     <GIC_SPI 103 IRQ_TYPE_LEVEL_HIGH 0>,
				     <GIC_SPI 104 IRQ_TYPE_LEVEL_HIGH 0>,
				     <GIC_SPI 105 IRQ_TYPE_LEVEL_HIGH 0>,
				     <GIC_SPI 106 IRQ_TYPE_LEVEL_HIGH 0>,
				     <GIC_SPI 107 IRQ_TYPE_LEVEL_HIGH 0>,
				     <GIC_SPI 108 IRQ_TYPE_LEVEL_HIGH 0>,
				     <GIC_SPI 109 IRQ_TYPE_LEVEL_HIGH 0>,
				     <GIC_SPI 110 IRQ_TYPE_LEVEL_HIGH 0>,
				     <GIC_SPI 111 IRQ_TYPE_LEVEL_HIGH 0>,
				     <GIC_SPI 112 IRQ_TYPE_LEVEL_HIGH 0>,
				     <GIC_SPI 113 IRQ_TYPE_LEVEL_HIGH 0>,
				     <GIC_SPI 114 IRQ_TYPE_LEVEL_HIGH 0>,
				     <GIC_SPI 115 IRQ_TYPE_LEVEL_HIGH 0>,
				     <GIC_SPI 116 IRQ_TYPE_LEVEL_HIGH 0>,
				     <GIC_SPI 117 IRQ_TYPE_LEVEL_HIGH 0>,
				     <GIC_SPI 118 IRQ_TYPE_LEVEL_HIGH 0>,
				     <GIC_SPI 181 IRQ_TYPE_LEVEL_HIGH 0>,
				     <GIC_SPI 182 IRQ_TYPE_LEVEL_HIGH 0>,
				     <GIC_SPI 183 IRQ_TYPE_LEVEL_HIGH 0>,
				     <GIC_SPI 184 IRQ_TYPE_LEVEL_HIGH 0>,
				     <GIC_SPI 185 IRQ_TYPE_LEVEL_HIGH 0>,
				     <GIC_SPI 186 IRQ_TYPE_LEVEL_HIGH 0>,
				     <GIC_SPI 187 IRQ_TYPE_LEVEL_HIGH 0>,
				     <GIC_SPI 188 IRQ_TYPE_LEVEL_HIGH 0>,
				     <GIC_SPI 189 IRQ_TYPE_LEVEL_HIGH 0>,
				     <GIC_SPI 190 IRQ_TYPE_LEVEL_HIGH 0>,
				     <GIC_SPI 191 IRQ_TYPE_LEVEL_HIGH 0>,
				     <GIC_SPI 192 IRQ_TYPE_LEVEL_HIGH 0>,
				     <GIC_SPI 315 IRQ_TYPE_LEVEL_HIGH 0>,
				     <GIC_SPI 316 IRQ_TYPE_LEVEL_HIGH 0>,
				     <GIC_SPI 317 IRQ_TYPE_LEVEL_HIGH 0>,
				     <GIC_SPI 318 IRQ_TYPE_LEVEL_HIGH 0>,
				     <GIC_SPI 319 IRQ_TYPE_LEVEL_HIGH 0>,
				     <GIC_SPI 320 IRQ_TYPE_LEVEL_HIGH 0>,
				     <GIC_SPI 321 IRQ_TYPE_LEVEL_HIGH 0>,
				     <GIC_SPI 322 IRQ_TYPE_LEVEL_HIGH 0>,
				     <GIC_SPI 323 IRQ_TYPE_LEVEL_HIGH 0>,
				     <GIC_SPI 324 IRQ_TYPE_LEVEL_HIGH 0>,
				     <GIC_SPI 325 IRQ_TYPE_LEVEL_HIGH 0>,
				     <GIC_SPI 326 IRQ_TYPE_LEVEL_HIGH 0>,
				     <GIC_SPI 327 IRQ_TYPE_LEVEL_HIGH 0>,
				     <GIC_SPI 328 IRQ_TYPE_LEVEL_HIGH 0>,
				     <GIC_SPI 329 IRQ_TYPE_LEVEL_HIGH 0>,
				     <GIC_SPI 330 IRQ_TYPE_LEVEL_HIGH 0>,
				     <GIC_SPI 331 IRQ_TYPE_LEVEL_HIGH 0>,
				     <GIC_SPI 332 IRQ_TYPE_LEVEL_HIGH 0>,
				     <GIC_SPI 333 IRQ_TYPE_LEVEL_HIGH 0>,
				     <GIC_SPI 334 IRQ_TYPE_LEVEL_HIGH 0>,
				     <GIC_SPI 335 IRQ_TYPE_LEVEL_HIGH 0>,
				     <GIC_SPI 336 IRQ_TYPE_LEVEL_HIGH 0>,
				     <GIC_SPI 337 IRQ_TYPE_LEVEL_HIGH 0>,
				     <GIC_SPI 338 IRQ_TYPE_LEVEL_HIGH 0>,
				     <GIC_SPI 339 IRQ_TYPE_LEVEL_HIGH 0>,
				     <GIC_SPI 340 IRQ_TYPE_LEVEL_HIGH 0>,
				     <GIC_SPI 341 IRQ_TYPE_LEVEL_HIGH 0>,
				     <GIC_SPI 342 IRQ_TYPE_LEVEL_HIGH 0>,
				     <GIC_SPI 343 IRQ_TYPE_LEVEL_HIGH 0>,
				     <GIC_SPI 344 IRQ_TYPE_LEVEL_HIGH 0>,
				     <GIC_SPI 345 IRQ_TYPE_LEVEL_HIGH 0>,
				     <GIC_SPI 395 IRQ_TYPE_LEVEL_HIGH 0>,
				     <GIC_SPI 396 IRQ_TYPE_LEVEL_HIGH 0>,
				     <GIC_SPI 397 IRQ_TYPE_LEVEL_HIGH 0>,
				     <GIC_SPI 398 IRQ_TYPE_LEVEL_HIGH 0>,
				     <GIC_SPI 399 IRQ_TYPE_LEVEL_HIGH 0>,
				     <GIC_SPI 400 IRQ_TYPE_LEVEL_HIGH 0>,
				     <GIC_SPI 401 IRQ_TYPE_LEVEL_HIGH 0>,
				     <GIC_SPI 402 IRQ_TYPE_LEVEL_HIGH 0>,
				     <GIC_SPI 403 IRQ_TYPE_LEVEL_HIGH 0>,
				     <GIC_SPI 404 IRQ_TYPE_LEVEL_HIGH 0>,
				     <GIC_SPI 405 IRQ_TYPE_LEVEL_HIGH 0>,
				     <GIC_SPI 406 IRQ_TYPE_LEVEL_HIGH 0>,
				     <GIC_SPI 407 IRQ_TYPE_LEVEL_HIGH 0>,
				     <GIC_SPI 408 IRQ_TYPE_LEVEL_HIGH 0>,
				     <GIC_SPI 409 IRQ_TYPE_LEVEL_HIGH 0>,
				     <GIC_SPI 418 IRQ_TYPE_LEVEL_HIGH 0>,
				     <GIC_SPI 419 IRQ_TYPE_LEVEL_HIGH 0>,
				     <GIC_SPI 412 IRQ_TYPE_LEVEL_HIGH 0>,
				     <GIC_SPI 421 IRQ_TYPE_LEVEL_HIGH 0>,
				     <GIC_SPI 706 IRQ_TYPE_LEVEL_HIGH 0>,
				     <GIC_SPI 423 IRQ_TYPE_LEVEL_HIGH 0>,
				     <GIC_SPI 424 IRQ_TYPE_LEVEL_HIGH 0>,
				     <GIC_SPI 425 IRQ_TYPE_LEVEL_HIGH 0>,
				     <GIC_SPI 689 IRQ_TYPE_LEVEL_HIGH 0>,
				     <GIC_SPI 690 IRQ_TYPE_LEVEL_HIGH 0>,
				     <GIC_SPI 691 IRQ_TYPE_LEVEL_HIGH 0>,
				     <GIC_SPI 692 IRQ_TYPE_LEVEL_HIGH 0>,
				     <GIC_SPI 693 IRQ_TYPE_LEVEL_HIGH 0>,
				     <GIC_SPI 694 IRQ_TYPE_LEVEL_HIGH 0>,
				     <GIC_SPI 695 IRQ_TYPE_LEVEL_HIGH 0>,
				     <GIC_SPI 696 IRQ_TYPE_LEVEL_HIGH 0>;
			dma-coherent;
		};


		intc: interrupt-controller@17100000 {
			compatible = "arm,gic-v3";
			reg = <0 0x17100000 0 0x10000>,
			      <0 0x17180000 0 0x200000>;
			ranges;
			#interrupt-cells = <4>;
			interrupt-controller;
			#redistributor-regions = <1>;
			redistributor-stride = <0 0x40000>;
			interrupts = <GIC_PPI 9 IRQ_TYPE_LEVEL_LOW 0>;
			#address-cells = <2>;
			#size-cells = <2>;

			ppi-partitions {
				ppi_cluster0: interrupt-partition-0 {
					affinity = <&cpu0 &cpu1 &cpu2 &cpu3>;
				};

				ppi_cluster1: interrupt-partition-1 {
					affinity = <&cpu4 &cpu5 &cpu6>;
				};

				ppi_cluster2: interrupt-partition-2 {
					affinity = <&cpu7>;
				};
			};
		};

		timer@17420000 {
			compatible = "arm,armv7-timer-mem";
			reg = <0 0x17420000 0 0x1000>;
			ranges = <0 0 0 0x20000000>;
			#address-cells = <1>;
			#size-cells = <1>;

			frame@17421000 {
				reg = <0x17421000 0x1000>,
				      <0x17422000 0x1000>;
				frame-number = <0>;
				interrupts = <GIC_SPI 8 IRQ_TYPE_LEVEL_HIGH 0>,
					     <GIC_SPI 6 IRQ_TYPE_LEVEL_HIGH 0>;
			};

			frame@17423000 {
				reg = <0x17423000 0x1000>;
				frame-number = <1>;
				interrupts = <GIC_SPI 9 IRQ_TYPE_LEVEL_HIGH 0>;
				status = "disabled";
			};

			frame@17425000 {
				reg = <0x17425000 0x1000>;
				frame-number = <2>;
				interrupts = <GIC_SPI 10 IRQ_TYPE_LEVEL_HIGH 0>;
				status = "disabled";
			};

			frame@17427000 {
				reg = <0x17427000 0x1000>;
				frame-number = <3>;
				interrupts = <GIC_SPI 11 IRQ_TYPE_LEVEL_HIGH 0>;
				status = "disabled";
			};

			frame@17429000 {
				reg = <0x17429000 0x1000>;
				frame-number = <4>;
				interrupts = <GIC_SPI 12 IRQ_TYPE_LEVEL_HIGH 0>;
				status = "disabled";
			};

			frame@1742b000 {
				reg = <0x1742b000 0x1000>;
				frame-number = <5>;
				interrupts = <GIC_SPI 13 IRQ_TYPE_LEVEL_HIGH 0>;
				status = "disabled";
			};

			frame@1742d000 {
				reg = <0x1742d000 0x1000>;
				frame-number = <6>;
				interrupts = <GIC_SPI 14 IRQ_TYPE_LEVEL_HIGH 0>;
				status = "disabled";
			};
		};


		apps_rsc: rsc@17a00000 {
			label = "apps_rsc";
			compatible = "qcom,rpmh-rsc";
			reg = <0 0x17a00000 0 0x10000>,
			      <0 0x17a10000 0 0x10000>,
			      <0 0x17a20000 0 0x10000>;
			reg-names = "drv-0", "drv-1", "drv-2";
			interrupts = <GIC_SPI 3 IRQ_TYPE_LEVEL_HIGH 0>,
				     <GIC_SPI 4 IRQ_TYPE_LEVEL_HIGH 0>,
				     <GIC_SPI 5 IRQ_TYPE_LEVEL_HIGH 0>;
			qcom,tcs-offset = <0xd00>;
			qcom,drv-id = <2>;
			qcom,tcs-config = <ACTIVE_TCS    3>, <SLEEP_TCS     2>,
					  <WAKE_TCS      2>, <CONTROL_TCS   0>;
			power-domains = <&cluster_pd>;

			apps_bcm_voter: bcm-voter {
				compatible = "qcom,bcm-voter";
			};

			rpmhcc: clock-controller {
				compatible = "qcom,sm7550-rpmh-clk";
				#clock-cells = <1>;
				clock-names = "xo";
				clocks = <&xo_board>;
			};

			rpmhpd: power-controller {
				compatible = "qcom,sm7550-rpmhpd";
				#power-domain-cells = <1>;
				operating-points-v2 = <&rpmhpd_opp_table>;

				rpmhpd_opp_table: opp-table {
					compatible = "operating-points-v2";

					rpmhpd_opp_ret: opp-16 {
						opp-level = <RPMH_REGULATOR_LEVEL_RETENTION>;
					};

					rpmhpd_opp_min_svs: opp-48 {
						opp-level = <RPMH_REGULATOR_LEVEL_MIN_SVS>;
					};

					rpmhpd_opp_low_svs_d2: opp-52 {
						opp-level = <RPMH_REGULATOR_LEVEL_LOW_SVS_D2>;
					};

					rpmhpd_opp_low_svs_d1: opp-56 {
						opp-level = <RPMH_REGULATOR_LEVEL_LOW_SVS_D1>;
					};

					rpmhpd_opp_low_svs_d0: opp-60 {
						opp-level = <RPMH_REGULATOR_LEVEL_LOW_SVS_D0>;
					};

					rpmhpd_opp_low_svs: opp-64 {
						opp-level = <RPMH_REGULATOR_LEVEL_LOW_SVS>;
					};

					rpmhpd_opp_low_svs_l1: opp-80 {
						opp-level = <RPMH_REGULATOR_LEVEL_LOW_SVS_L1>;
					};

					rpmhpd_opp_svs: opp-128 {
						opp-level = <RPMH_REGULATOR_LEVEL_SVS>;
					};

					rpmhpd_opp_svs_l0: opp-144 {
						opp-level = <RPMH_REGULATOR_LEVEL_SVS_L0>;
					};

					rpmhpd_opp_svs_l1: opp-192 {
						opp-level = <RPMH_REGULATOR_LEVEL_SVS_L1>;
					};

					rpmhpd_opp_nom: opp-256 {
						opp-level = <RPMH_REGULATOR_LEVEL_NOM>;
					};

					rpmhpd_opp_nom_l1: opp-320 {
						opp-level = <RPMH_REGULATOR_LEVEL_NOM_L1>;
					};

					rpmhpd_opp_nom_l2: opp-336 {
						opp-level = <RPMH_REGULATOR_LEVEL_NOM_L2>;
					};

					rpmhpd_opp_turbo: opp-384 {
						opp-level = <RPMH_REGULATOR_LEVEL_TURBO>;
					};

					rpmhpd_opp_turbo_l1: opp-416 {
						opp-level = <RPMH_REGULATOR_LEVEL_TURBO_L1>;
					};
				};
			};
		};

		cpufreq_hw: cpufreq@17d91000 {
			compatible = "qcom,sm7550-cpufreq-epss", "qcom,cpufreq-epss";
			reg = <0 0x17d91000 0 0x1000>,
			      <0 0x17d92000 0 0x1000>,
			      <0 0x17d93000 0 0x1000>;
			reg-names = "freq-domain0", "freq-domain1", "freq-domain2";
			clocks = <&bi_tcxo_div2>, <&gcc GCC_GPLL0>;
			clock-names = "xo", "alternate";
			interrupts = <GIC_SPI 30 IRQ_TYPE_LEVEL_HIGH 0>,
				     <GIC_SPI 31 IRQ_TYPE_LEVEL_HIGH 0>,
				     <GIC_SPI 19 IRQ_TYPE_LEVEL_HIGH 0>;
			interrupt-names = "dcvsh-irq-0", "dcvsh-irq-1", "dcvsh-irq-2";
			#freq-domain-cells = <1>;
			#clock-cells = <1>;
		};

		pmu@24091000 {
			compatible = "qcom,sm7550-llcc-bwmon", "qcom,sc7280-llcc-bwmon";
			reg = <0 0x24091000 0 0x1000>;
			interrupts = <GIC_SPI 81 IRQ_TYPE_LEVEL_HIGH 0>;
			interconnects = <&mc_virt MASTER_LLCC QCOM_ICC_TAG_ACTIVE_ONLY
					 &mc_virt SLAVE_EBI1 QCOM_ICC_TAG_ACTIVE_ONLY>;

			operating-points-v2 = <&llcc_bwmon_opp_table>;

			llcc_bwmon_opp_table: opp-table {
				compatible = "operating-points-v2";

				opp-0 {
					opp-peak-kBps = <2086000>;
				};

				opp-1 {
					opp-peak-kBps = <2929000>;
				};

				opp-2 {
					opp-peak-kBps = <5931000>;
				};

				opp-3 {
					opp-peak-kBps = <6515000>;
				};

				opp-4 {
					opp-peak-kBps = <7980000>;
				};

				opp-5 {
					opp-peak-kBps = <10437000>;
				};

				opp-6 {
					opp-peak-kBps = <12157000>;
				};
			};
		};

		pmu@240b6400 {
			compatible = "qcom,sm7550-cpu-bwmon", "qcom,sdm845-bwmon";
			reg = <0 0x240b6400 0 0x300>;
			interrupts = <GIC_SPI 581 IRQ_TYPE_LEVEL_HIGH 0>;
			interconnects = <&gem_noc MASTER_APPSS_PROC QCOM_ICC_TAG_ACTIVE_ONLY
					 &gem_noc SLAVE_LLCC QCOM_ICC_TAG_ACTIVE_ONLY>;

			operating-points-v2 = <&cpu_bwmon_opp_table>;

			cpu_bwmon_opp_table: opp-table {
				compatible = "operating-points-v2";

				opp-0 {
					opp-peak-kBps = <4577000>;
				};

				opp-1 {
					opp-peak-kBps = <7110000>;
				};

				opp-2 {
					opp-peak-kBps = <9155000>;
				};

				opp-3 {
					opp-peak-kBps = <12298000>;
				};

				opp-4 {
					opp-peak-kBps = <16265000>;
				};
			};
		};

		gem_noc: interconnect@24100000 {
			compatible = "qcom,sm7550-gem-noc";
			reg = <0 0x24100000 0 0xBD080>;
			#interconnect-cells = <2>;
			qcom,bcm-voters = <&apps_bcm_voter>;
		};

		system-cache-controller@25000000 {
			compatible = "qcom,sm7550-llcc";
			reg = <0 0x25000000 0 0x200000>,
			      <0 0x25200000 0 0x200000>,
			      <0 0x25800000 0 0x200000>;
			reg-names = "llcc0_base",
				    "llcc1_base",
				    "llcc_broadcast_base";
			interrupts = <GIC_SPI 266 IRQ_TYPE_LEVEL_HIGH 0>;
		};

		nsp_noc: interconnect@320c0000 {
			compatible = "qcom,sm7550-nsp-noc";
			reg = <0 0x320c0000 0 0xe080>;
			#interconnect-cells = <2>;
			qcom,bcm-voters = <&apps_bcm_voter>;
		};


		remoteproc_cdsp: remoteproc@32300000 {
			compatible = "qcom,sm7550-cdsp-pas";
			reg = <0x0 0x32300000 0x0 0x10000>;

			interrupts-extended = <&intc GIC_SPI 578 IRQ_TYPE_EDGE_RISING 0>,
					      <&smp2p_cdsp_in 0 IRQ_TYPE_EDGE_RISING>,
					      <&smp2p_cdsp_in 1 IRQ_TYPE_EDGE_RISING>,
					      <&smp2p_cdsp_in 2 IRQ_TYPE_EDGE_RISING>,
					      <&smp2p_cdsp_in 3 IRQ_TYPE_EDGE_RISING>;
			interrupt-names = "wdog", "fatal", "ready",
					  "handover", "stop-ack";

			clocks = <&rpmhcc RPMH_CXO_CLK>;
			clock-names = "xo";

			power-domains = <&rpmhpd RPMHPD_CX>,
					<&rpmhpd RPMHPD_MXC>,
					<&rpmhpd RPMHPD_NSP>;
			power-domain-names = "cx", "mxc", "nsp";

			interconnects = <&nsp_noc MASTER_CDSP_PROC QCOM_ICC_TAG_ALWAYS
					 &mc_virt SLAVE_EBI1 QCOM_ICC_TAG_ALWAYS>;

			memory-region = <&cdsp_mem>, <&q6_cdsp_dtb_mem>;

			qcom,qmp = <&aoss_qmp>;

			qcom,smem-states = <&smp2p_cdsp_out 0>;
			qcom,smem-state-names = "stop";

			status = "disabled";

			glink-edge {
				interrupts-extended = <&ipcc IPCC_CLIENT_CDSP
							     IPCC_MPROC_SIGNAL_GLINK_QMP
							     IRQ_TYPE_EDGE_RISING>;
				mboxes = <&ipcc IPCC_CLIENT_CDSP
						IPCC_MPROC_SIGNAL_GLINK_QMP>;

				label = "cdsp";
				qcom,remote-pid = <5>;

				fastrpc {
					compatible = "qcom,fastrpc";
					qcom,glink-channels = "fastrpcglink-apps-dsp";
					label = "cdsp";
					qcom,non-secure-domain;
					#address-cells = <1>;
					#size-cells = <0>;

					compute-cb@1 {
						compatible = "qcom,fastrpc-compute-cb";
						reg = <1>;
						iommus = <&apps_smmu 0x0C01 0x0000>;;
						dma-coherent;
					};

					compute-cb@2 {
						compatible = "qcom,fastrpc-compute-cb";
						reg = <2>;
						iommus = <&apps_smmu 0x0C02 0x0000>;
						dma-coherent;
					};

					compute-cb@3 {
						compatible = "qcom,fastrpc-compute-cb";
						reg = <3>;
						iommus = <&apps_smmu 0x0C03 0x0000>;
						dma-coherent;
					};

					compute-cb@4 {
						compatible = "qcom,fastrpc-compute-cb";
						reg = <4>;
						iommus = <&apps_smmu 0x0C04 0x0000>;
						dma-coherent;
					};

					compute-cb@5 {
						compatible = "qcom,fastrpc-compute-cb";
						reg = <5>;
						iommus = <&apps_smmu 0x0C05 0x0000>;
						dma-coherent;
					};

					compute-cb@6 {
						compatible = "qcom,fastrpc-compute-cb";
						reg = <6>;
						iommus = <&apps_smmu 0x0C06 0x0000>;
						dma-coherent;
					};

					compute-cb@7 {
						compatible = "qcom,fastrpc-compute-cb";
						reg = <7>;
						iommus = <&apps_smmu 0x0C07 0x0000>;
						dma-coherent;
					};

					compute-cb@8 {
						compatible = "qcom,fastrpc-compute-cb";
						reg = <8>;
						iommus = <&apps_smmu 0x0C08 0x0000>;
						dma-coherent;
					};

					/* note: secure cb9 in downstream */
				};
			};
		};
    };

	thermal-zones {
        aoss-0 {
            thermal-sensors = <&tsens0 0>;

            trips {
                thermal-engine-config {
                    temperature = <125000>;
                    hysteresis = <1000>;
                    type = "passive";
                };

                reset-mon-config {
                    temperature = <115000>;
                    hysteresis = <5000>;
                    type = "passive";
                };
            };
        };

        cpuss0-thermal {
			thermal-sensors = <&tsens0 1>;

			trips {
				thermal-engine-config {
					temperature = <125000>;
					hysteresis = <1000>;
					type = "passive";
				};

				reset-mon-config {
					temperature = <115000>;
					hysteresis = <5000>;
					type = "passive";
				};
			};
		};

		cpuss1-thermal {
			thermal-sensors = <&tsens0 2>;

			trips {
				thermal-engine-config {
					temperature = <125000>;
					hysteresis = <1000>;
					type = "passive";
				};

				reset-mon-config {
					temperature = <115000>;
					hysteresis = <5000>;
					type = "passive";
				};
			};
		};

        cpu4-left-thermal {
			thermal-sensors = <&tsens0 3>;

			trips {
				cpu4-critical {
					temperature = <110000>;
					hysteresis = <1000>;
					type = "critical";
				};
			};
		};

        cpu4-right-thermal {
			thermal-sensors = <&tsens0 4>;

			trips {
				cpu4-critical {
					temperature = <110000>;
					hysteresis = <1000>;
					type = "critical";
				};
			};
		};

        cpu5-left-thermal {
			thermal-sensors = <&tsens0 5>;

			trips {
				cpu5-critical {
					temperature = <110000>;
					hysteresis = <1000>;
					type = "critical";
				};
			};
		};

        cpu5-right-thermal {
			thermal-sensors = <&tsens0 6>;

			trips {
				cpu5-critical {
					temperature = <110000>;
					hysteresis = <1000>;
					type = "critical";
				};
			};
		};

        cpu6-left-thermal {
			thermal-sensors = <&tsens0 7>;

			trips {
				cpu6-critical {
					temperature = <110000>;
					hysteresis = <1000>;
					type = "critical";
				};
			};
		};

        cpu6-right-thermal {
			thermal-sensors = <&tsens0 8>;

			trips {
				cpu6-critical {
					temperature = <110000>;
					hysteresis = <1000>;
					type = "critical";
				};
			};
		};

        cpu7-left-thermal {
			thermal-sensors = <&tsens0 9>;

			trips {
				cpu7-critical {
					temperature = <110000>;
					hysteresis = <1000>;
					type = "critical";
				};
			};
		};

        cpu7-right-thermal {
			thermal-sensors = <&tsens0 10>;

			trips {
				cpu7-critical {
					temperature = <110000>;
					hysteresis = <1000>;
					type = "critical";
				};
			};
		};

        cpu0-thermal {
			thermal-sensors = <&tsens0 11>;

			trips {
				cpu0-critical {
					temperature = <110000>;
					hysteresis = <1000>;
					type = "critical";
				};
			};
		};

        cpu1-thermal {
			thermal-sensors = <&tsens0 12>;

			trips {
				cpu1-critical {
					temperature = <110000>;
					hysteresis = <1000>;
					type = "critical";
				};
			};
		};

        cpu2-thermal {
			thermal-sensors = <&tsens0 13>;

			trips {
				cpu2-critical {
					temperature = <110000>;
					hysteresis = <1000>;
					type = "critical";
				};
			};
		};

        cpu3-thermal {
			thermal-sensors = <&tsens0 14>;

			trips {
				cpu3-critical {
					temperature = <110000>;
					hysteresis = <1000>;
					type = "critical";
				};
			};
		};


		mem-thermal {
			polling-delay-passive = <10>;

			thermal-sensors = <&tsens1 15>;

			trips {
				thermal-engine-config {
					temperature = <125000>;
					hysteresis = <1000>;
					type = "passive";
				};

				ddr_config0: ddr0-config {
					temperature = <90000>;
					hysteresis = <5000>;
					type = "passive";
				};

				reset-mon-config {
					temperature = <115000>;
					hysteresis = <5000>;
					type = "passive";
				};
			};
		};

		aoss1-thermal {
			thermal-sensors = <&tsens1 0>;

			trips {
				thermal-engine-config {
					temperature = <125000>;
					hysteresis = <1000>;
					type = "passive";
				};

				reset-mon-config {
					temperature = <115000>;
					hysteresis = <5000>;
					type = "passive";
				};
			};
		};


		modem0-thermal {
			thermal-sensors = <&tsens1 4>;

			trips {
				thermal-engine-config {
					temperature = <125000>;
					hysteresis = <1000>;
					type = "passive";
				};

				mdmss0_config0: mdmss0-config0 {
					temperature = <102000>;
					hysteresis = <3000>;
					type = "passive";
				};

				mdmss0_config1: mdmss0-config1 {
					temperature = <105000>;
					hysteresis = <3000>;
					type = "passive";
				};

				reset-mon-config {
					temperature = <115000>;
					hysteresis = <5000>;
					type = "passive";
				};
			};
		};

		modem1-thermal {
			thermal-sensors = <&tsens1 5>;

			trips {
				thermal-engine-config {
					temperature = <125000>;
					hysteresis = <1000>;
					type = "passive";
				};

				mdmss1_config0: mdmss1-config0 {
					temperature = <102000>;
					hysteresis = <3000>;
					type = "passive";
				};

				mdmss1_config1: mdmss1-config1 {
					temperature = <105000>;
					hysteresis = <3000>;
					type = "passive";
				};

				reset-mon-config {
					temperature = <115000>;
					hysteresis = <5000>;
					type = "passive";
				};
			};
		};

		modem2-thermal {
			thermal-sensors = <&tsens1 6>;

			trips {
				thermal-engine-config {
					temperature = <125000>;
					hysteresis = <1000>;
					type = "passive";
				};

				mdmss2_config0: mdmss2-config0 {
					temperature = <102000>;
					hysteresis = <3000>;
					type = "passive";
				};

				mdmss2_config1: mdmss2-config1 {
					temperature = <105000>;
					hysteresis = <3000>;
					type = "passive";
				};

				reset-mon-config {
					temperature = <115000>;
					hysteresis = <5000>;
					type = "passive";
				};
			};
		};

		modem3-thermal {
			thermal-sensors = <&tsens1 7>;

			trips {
				thermal-engine-config {
					temperature = <125000>;
					hysteresis = <1000>;
					type = "passive";
				};

				mdmss3_config0: mdmss3-config0 {
					temperature = <102000>;
					hysteresis = <3000>;
					type = "passive";
				};

				mdmss3_config1: mdmss3-config1 {
					temperature = <105000>;
					hysteresis = <3000>;
					type = "passive";
				};

				reset-mon-config {
					temperature = <115000>;
					hysteresis = <5000>;
					type = "passive";
				};
			};
		};

		camera0-thermal {
			thermal-sensors = <&tsens1 8>;

			trips {
				thermal-engine-config {
					temperature = <125000>;
					hysteresis = <1000>;
					type = "passive";
				};

				reset-mon-config {
					temperature = <115000>;
					hysteresis = <5000>;
					type = "passive";
				};
			};
		};

		gpuss-0-thermal {
			polling-delay-passive = <10>;

			thermal-sensors = <&tsens1 9>;

			cooling-maps {
				map0 {
					trip = <&gpu0_alert0>;
					cooling-device = <&gpu THERMAL_NO_LIMIT THERMAL_NO_LIMIT>;
				};
			};

			trips {
				gpu0_alert0: trip-point0 {
					temperature = <85000>;
					hysteresis = <1000>;
					type = "passive";
				};

				trip-point1 {
					temperature = <90000>;
					hysteresis = <1000>;
					type = "hot";
				};

				trip-point2 {
					temperature = <110000>;
					hysteresis = <1000>;
					type = "critical";
				};
			};
		};


		gpuss-1-thermal {
			polling-delay-passive = <10>;

			thermal-sensors = <&tsens1 10>;

			cooling-maps {
				map0 {
					trip = <&gpu1_alert0>;
					cooling-device = <&gpu THERMAL_NO_LIMIT THERMAL_NO_LIMIT>;
				};
			};

			trips {
				gpu1_alert0: trip-point0 {
					temperature = <85000>;
					hysteresis = <1000>;
					type = "passive";
				};

				trip-point1 {
					temperature = <90000>;
					hysteresis = <1000>;
					type = "hot";
				};

				trip-point2 {
					temperature = <110000>;
					hysteresis = <1000>;
					type = "critical";
				};
			};
		};

	};

	timer {
		compatible = "arm,armv8-timer";
		interrupts = <GIC_PPI 13 IRQ_TYPE_LEVEL_LOW 0>,
			     <GIC_PPI 14 IRQ_TYPE_LEVEL_LOW 0>,
			     <GIC_PPI 11 IRQ_TYPE_LEVEL_LOW 0>,
			     <GIC_PPI 10 IRQ_TYPE_LEVEL_LOW 0>;
	};
};
